BO_ 57 SRS_39: 3 SRS
 SG_ NEW_SIGNAL_2 : 7|8@0+ (1,0) [0|0] "" XXX
 SG_ NEW_SIGNAL_3 : 14|9@0+ (1,0) [0|0] "" XXX
 SG_ NEW_SIGNAL_1 : 15|1@0+ (1,0) [0|0] "" XXX
 SG_ CHECKSUM : 19|4@0+ (1,0) [0|0] "" XXX
 SG_ COUNTER : 21|2@0+ (1,0) [0|0] "" XXX

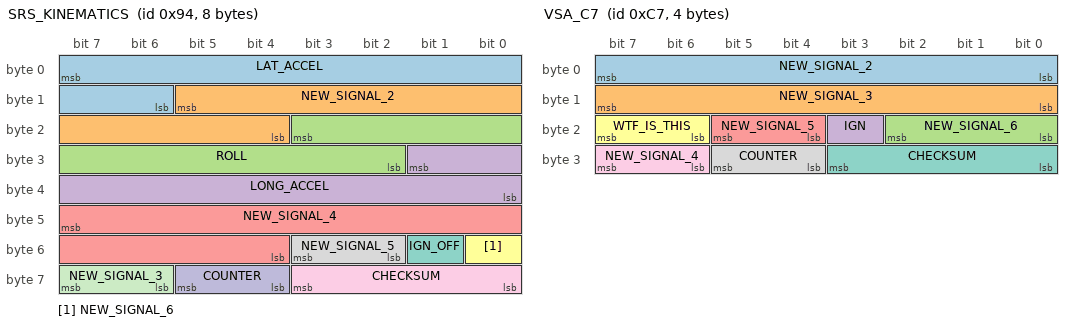
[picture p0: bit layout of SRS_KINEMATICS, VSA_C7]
BO_ 148 SRS_KINEMATICS: 8 SRS
 SG_ LAT_ACCEL : 7|10@0+ (-0.035,17.92) [0|0] "" XXX
 SG_ NEW_SIGNAL_2 : 13|10@0+ (1,0) [0|0] "" XXX
 SG_ ROLL : 19|10@0+ (1,-507) [0|0] "" XXX
 SG_ LONG_ACCEL : 25|10@0+ (-0.035,17.92) [0|0] "" XXX
 SG_ NEW_SIGNAL_4 : 47|12@0+ (1,0) [0|0] "" XXX
 SG_ NEW_SIGNAL_6 : 48|1@0+ (1,0) [0|0] "" XXX
 SG_ IGN_OFF : 49|1@0+ (1,0) [0|0] "" XXX
 SG_ NEW_SIGNAL_5 : 51|2@0+ (1,0) [0|0] "" XXX
 SG_ CHECKSUM : 59|4@0+ (1,0) [0|0] "" XXX
 SG_ COUNTER : 61|2@0+ (1,0) [0|0] "" XXX
 SG_ NEW_SIGNAL_3 : 63|2@0+ (1,0) [0|0] "" XXX

BO_ 199 VSA_C7: 4 VSA
 SG_ NEW_SIGNAL_2 : 7|8@0+ (1,0) [0|0] "" XXX
 SG_ NEW_SIGNAL_3 : 15|8@0+ (1,0) [0|0] "" XXX
 SG_ NEW_SIGNAL_6 : 18|3@0+ (1,0) [0|0] "" XXX
 SG_ IGN : 19|1@0+ (1,0) [0|0] "" XXX
 SG_ NEW_SIGNAL_5 : 21|2@0+ (1,0) [0|0] "" XXX
 SG_ WTF_IS_THIS : 23|2@0+ (1,0) [0|0] "" XXX
 SG_ CHECKSUM : 27|4@0+ (1,0) [0|0] "" XXX
 SG_ COUNTER : 29|2@0+ (1,0) [0|0] "" XXX
 SG_ NEW_SIGNAL_4 : 31|2@0+ (1,0) [0|0] "" XXX

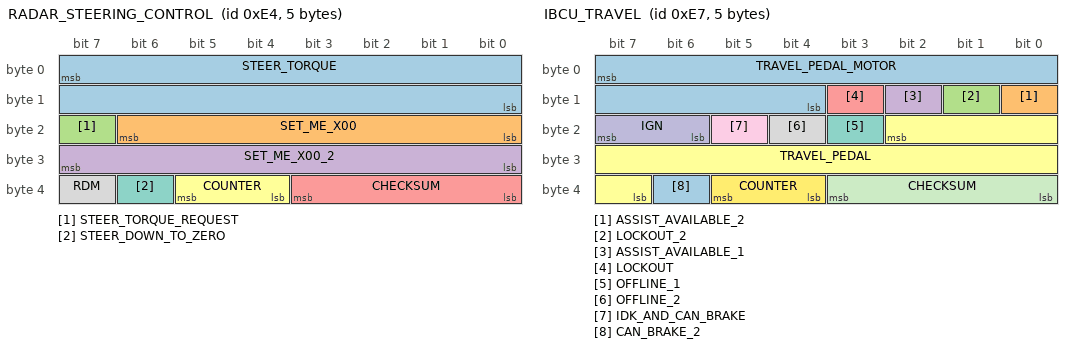
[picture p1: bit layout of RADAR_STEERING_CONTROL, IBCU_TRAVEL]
BO_ 228 RADAR_STEERING_CONTROL: 5 RADAR
 SG_ STEER_TORQUE : 7|16@0- (1,0) [0|0] "" XXX
 SG_ SET_ME_X00 : 22|7@0+ (1,0) [0|0] "" XXX
 SG_ STEER_TORQUE_REQUEST : 23|1@0+ (1,0) [0|0] "" XXX
 SG_ SET_ME_X00_2 : 31|8@0+ (1,0) [0|0] "" XXX
 SG_ CHECKSUM : 35|4@0+ (1,0) [0|0] "" XXX
 SG_ COUNTER : 37|2@0+ (1,0) [0|0] "" XXX
 SG_ STEER_DOWN_TO_ZERO : 38|1@0+ (1,0) [0|0] "" XXX
 SG_ RDM : 39|1@0+ (1,0) [0|0] "" XXX

BO_ 229 BOSCH_SUPPLEMENTAL_1: 8 CAM
 SG_ SET_ME_X04 : 0|8@1+ (1,0) [0|0] "" XXX
 SG_ SET_ME_X00 : 8|8@1+ (1,0) [0|0] "" XXX
 SG_ SET_ME_X80 : 16|8@1+ (1,0) [0|0] "" XXX
 SG_ SET_ME_X10 : 24|8@1+ (1,0) [0|0] "" XXX
 SG_ CHECKSUM : 59|4@0+ (1,0) [0|0] "" XXX
 SG_ COUNTER : 61|2@0+ (1,0) [0|0] "" XXX

BO_ 231 IBCU_TRAVEL: 5 IBCU
 SG_ TRAVEL_PEDAL_MOTOR : 7|12@0+ (1,0) [0|0] "" XXX
 SG_ ASSIST_AVAILABLE_2 : 8|1@0+ (1,0) [0|0] "" XXX
 SG_ LOCKOUT_2 : 9|1@0+ (1,0) [0|0] "" XXX
 SG_ ASSIST_AVAILABLE_1 : 10|1@0+ (1,0) [0|0] "" XXX
 SG_ LOCKOUT : 11|1@0+ (1,0) [0|0] "" XXX
 SG_ TRAVEL_PEDAL : 18|12@0+ (1,0) [0|0] "" XXX
 SG_ OFFLINE_1 : 19|1@0+ (1,0) [0|0] "" XXX
 SG_ OFFLINE_2 : 20|1@0+ (1,0) [0|0] "" XXX
 SG_ IDK_AND_CAN_BRAKE : 21|1@0+ (1,0) [0|0] "" XXX
 SG_ IGN : 23|2@0+ (1,0) [0|0] "" XXX
 SG_ CHECKSUM : 35|4@0+ (1,0) [0|0] "" XXX
 SG_ COUNTER : 37|2@0+ (1,0) [0|0] "" XXX
 SG_ CAN_BRAKE_2 : 38|1@0+ (1,0) [0|0] "" XXX

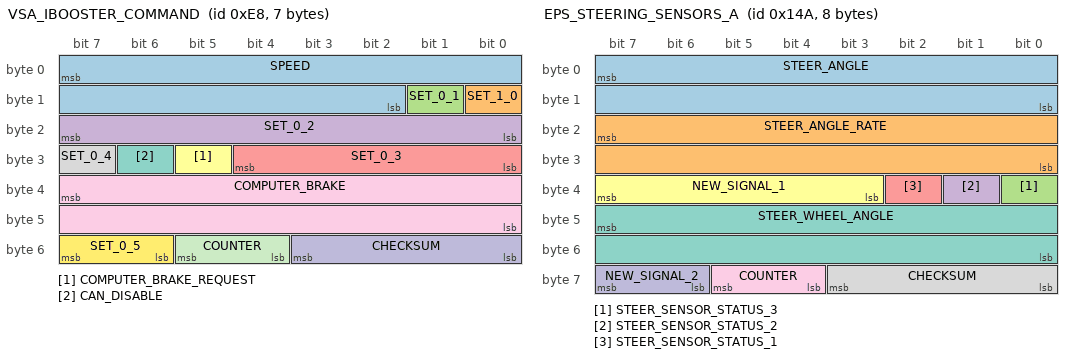
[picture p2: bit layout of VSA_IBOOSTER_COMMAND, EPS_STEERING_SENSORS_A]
BO_ 232 VSA_IBOOSTER_COMMAND: 7 VSA
 SG_ SPEED : 7|14@0+ (0.06,0) [0|0] "" XXX
 SG_ SET_1_0 : 8|1@0+ (1,0) [0|0] "" XXX
 SG_ SET_0_1 : 9|1@0+ (1,0) [0|0] "" XXX
 SG_ SET_0_2 : 23|8@0+ (1,0) [0|0] "" XXX
 SG_ SET_0_3 : 28|5@0+ (1,0) [0|0] "" XXX
 SG_ COMPUTER_BRAKE_REQUEST : 29|1@0+ (1,0) [0|0] "" XXX
 SG_ CAN_DISABLE : 30|1@0+ (1,0) [0|0] "" XXX
 SG_ SET_0_4 : 31|1@0+ (1,0) [0|0] "" XXX
 SG_ COMPUTER_BRAKE : 39|16@0+ (1,-32256) [0|0] "" XXX
 SG_ CHECKSUM : 51|4@0+ (1,0) [0|0] "" XXX
 SG_ COUNTER : 53|2@0+ (1,0) [0|0] "" XXX
 SG_ SET_0_5 : 55|2@0+ (1,0) [0|0] "" XXX

BO_ 304 PCM_GATEWAYFORWARD_GAS_PEDAL_2: 8 PCM
 SG_ ENGINE_TORQUE_ESTIMATE : 7|16@0- (0.1,0) [0|0] "" XXX
 SG_ ENGINE_TORQUE_REQUEST : 23|16@0- (0.1,0) [0|0] "" XXX
 SG_ CAR_GAS : 39|8@0+ (0.465116279,0) [0|0] "" XXX
 SG_ NEW_SIGNAL_8 : 40|1@0+ (1,0) [0|1] "" XXX
 SG_ RELATED_IDLE_STOP : 41|1@0+ (1,0) [0|0] "" XXX
 SG_ NEW_SIGNAL_6 : 43|2@0+ (1,0) [0|3] "" XXX
 SG_ GAS_PRESSED : 44|1@0+ (1,0) [0|0] "" XXX
 SG_ NEW_SIGNAL_3 : 45|1@0+ (1,0) [0|1] "" XXX
 SG_ RELATED_IDLE_STOP2 : 46|1@0+ (1,0) [0|0] "" XXX
 SG_ NEW_SIGNAL_2 : 47|1@0+ (1,0) [0|1] "" XXX
 SG_ NEUTRAL : 48|1@0+ (1,0) [0|1] "" XXX
 SG_ REVERSE : 49|1@0+ (1,0) [0|1] "" XXX
 SG_ CLUTCH : 50|1@0+ (1,0) [0|0] "" XXX
 SG_ NEW_SIGNAL_7 : 51|1@0+ (1,0) [0|1] "" XXX
 SG_ NEW_SIGNAL_1 : 52|1@0+ (1,0) [0|1] "" XXX
 SG_ NEW_SIGNAL_5 : 55|3@0+ (1,0) [0|7] "" XXX
 SG_ CHECKSUM : 59|4@0+ (1,0) [0|0] "" XXX
 SG_ COUNTER : 61|2@0+ (1,0) [0|0] "" XXX

BO_ 330 EPS_STEERING_SENSORS_A: 8 EPS
 SG_ STEER_ANGLE : 7|16@0- (-0.1,0) [0|0] "" XXX
 SG_ STEER_ANGLE_RATE : 23|16@0- (-1,0) [0|0] "" XXX
 SG_ STEER_SENSOR_STATUS_3 : 32|1@0+ (1,0) [0|0] "" XXX
 SG_ STEER_SENSOR_STATUS_2 : 33|1@0+ (1,0) [0|0] "" XXX
 SG_ STEER_SENSOR_STATUS_1 : 34|1@0+ (1,0) [0|0] "" XXX
 SG_ NEW_SIGNAL_1 : 39|5@0+ (1,0) [0|0] "" XXX
 SG_ STEER_WHEEL_ANGLE : 47|16@0- (-0.1,0) [0|0] "" XXX
 SG_ CHECKSUM : 59|4@0+ (1,0) [0|0] "" XXX
 SG_ COUNTER : 61|2@0+ (1,0) [0|0] "" XXX
 SG_ NEW_SIGNAL_2 : 63|2@0+ (1,0) [0|0] "" XXX

BO_ 340 CRV_IDK_154: 8 XXX
 SG_ NEW_SIGNAL_1 : 7|8@0+ (1,0) [0|0] "" XXX
 SG_ NEW_SIGNAL_2 : 15|8@0+ (1,0) [0|0] "" XXX
 SG_ NEW_SIGNAL_3 : 23|8@0+ (1,0) [0|0] "" XXX
 SG_ NEW_SIGNAL_4 : 31|32@0+ (1,0) [0|0] "" XXX
 SG_ CHECKSUM : 59|4@0+ (1,0) [0|0] "" XXX
 SG_ COUNTER : 61|2@0+ (1,0) [0|0] "" XXX
 SG_ NEW_SIGNAL_5 : 63|2@0+ (1,0) [0|0] "" XXX

BO_ 342 STEERING_SENSORS_B: 6 EPS
 SG_ STEER_ANGLE : 7|16@0- (-0.1,0) [0|0] "" XXX
 SG_ STEER_ANGLE_RATE : 23|16@0- (-1,0) [0|0] "" XXX
 SG_ CHECKSUM : 43|4@0+ (1,0) [0|0] "" XXX
 SG_ COUNTER : 45|2@0+ (1,0) [0|0] "" XXX

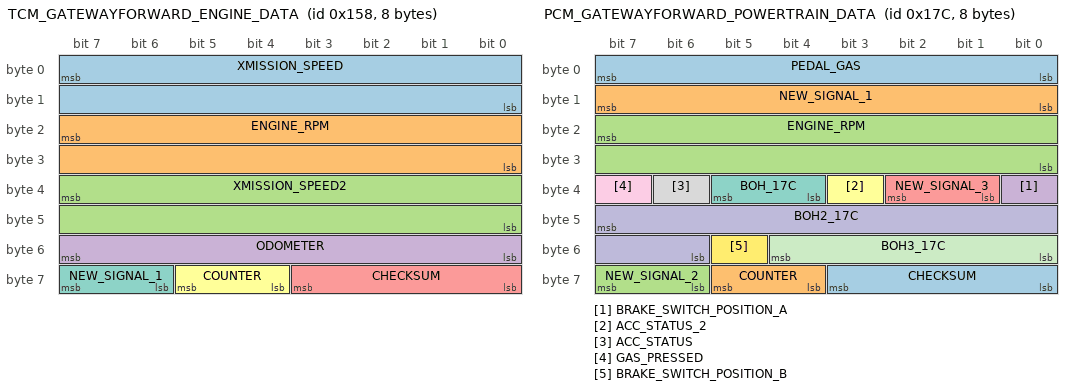
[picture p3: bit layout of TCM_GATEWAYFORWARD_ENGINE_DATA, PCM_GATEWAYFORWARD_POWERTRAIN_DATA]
BO_ 344 TCM_GATEWAYFORWARD_ENGINE_DATA: 8 TCM
 SG_ XMISSION_SPEED : 7|16@0+ (0.01,0) [0|0] "" XXX
 SG_ ENGINE_RPM : 23|16@0+ (1,0) [0|0] "" XXX
 SG_ XMISSION_SPEED2 : 39|16@0+ (0.01,0) [0|0] "" XXX
 SG_ ODOMETER : 55|8@0+ (10,0) [0|0] "" XXX
 SG_ CHECKSUM : 59|4@0+ (1,0) [0|0] "" XXX
 SG_ COUNTER : 61|2@0+ (1,0) [0|0] "" XXX
 SG_ NEW_SIGNAL_1 : 63|2@0+ (1,0) [0|0] "" XXX

BO_ 380 PCM_GATEWAYFORWARD_POWERTRAIN_DATA: 8 PCM
 SG_ PEDAL_GAS : 7|8@0+ (0.465116279,0) [0|0] "" XXX
 SG_ NEW_SIGNAL_1 : 15|8@0+ (1,0) [0|255] "" XXX
 SG_ ENGINE_RPM : 23|16@0+ (1,0) [0|0] "" XXX
 SG_ BRAKE_SWITCH_POSITION_A : 32|1@0+ (1,0) [0|0] "" XXX
 SG_ NEW_SIGNAL_3 : 34|2@0+ (1,0) [0|0] "" XXX
 SG_ ACC_STATUS_2 : 35|1@0+ (1,0) [0|0] "" XXX
 SG_ BOH_17C : 37|2@0+ (1,0) [0|0] "" XXX
 SG_ ACC_STATUS : 38|1@0+ (1,0) [0|0] "" XXX
 SG_ GAS_PRESSED : 39|1@0+ (1,0) [0|0] "" XXX
 SG_ BOH2_17C : 47|10@0+ (1,0) [0|0] "" XXX
 SG_ BOH3_17C : 52|5@0+ (1,0) [0|0] "" XXX
 SG_ BRAKE_SWITCH_POSITION_B : 53|1@0+ (1,0) [0|0] "" XXX
 SG_ CHECKSUM : 59|4@0+ (1,0) [0|0] "" XXX
 SG_ COUNTER : 61|2@0+ (1,0) [0|0] "" XXX
 SG_ NEW_SIGNAL_2 : 63|2@0+ (1,0) [0|0] "" XXX

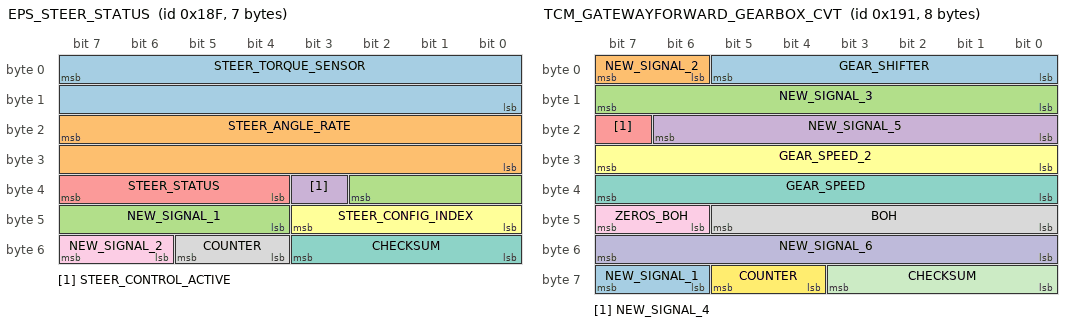
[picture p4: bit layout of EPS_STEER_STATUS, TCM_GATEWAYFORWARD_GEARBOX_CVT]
BO_ 399 EPS_STEER_STATUS: 7 EPS
 SG_ STEER_TORQUE_SENSOR : 7|16@0- (-0.001,0) [0|0] "" XXX
 SG_ STEER_ANGLE_RATE : 23|16@0- (-0.1,0) [0|0] "" XXX
 SG_ NEW_SIGNAL_1 : 34|7@0+ (1,0) [0|0] "" XXX
 SG_ STEER_CONTROL_ACTIVE : 35|1@0+ (1,0) [0|0] "" XXX
 SG_ STEER_STATUS : 39|4@0+ (1,0) [0|0] "" XXX
 SG_ STEER_CONFIG_INDEX : 43|4@0+ (1,0) [0|0] "" XXX
 SG_ CHECKSUM : 51|4@0+ (1,0) [0|0] "" XXX
 SG_ COUNTER : 53|2@0+ (1,0) [0|0] "" XXX
 SG_ NEW_SIGNAL_2 : 55|2@0+ (1,0) [0|0] "" XXX

BO_ 401 TCM_GATEWAYFORWARD_GEARBOX_CVT: 8 TCM
 SG_ GEAR_SHIFTER : 5|6@0+ (1,0) [0|0] "" XXX
 SG_ NEW_SIGNAL_2 : 7|2@0+ (1,0) [0|0] "" XXX
 SG_ NEW_SIGNAL_3 : 15|8@0+ (1,0) [0|0] "" XXX
 SG_ NEW_SIGNAL_5 : 22|7@0+ (1,0) [0|0] "" XXX
 SG_ NEW_SIGNAL_4 : 23|1@0+ (1,0) [0|0] "" XXX
 SG_ GEAR_SPEED_2 : 31|8@0+ (-0.243,41.067) [0|0] "" XXX
 SG_ GEAR_SPEED : 39|8@0+ (-0.243,41.067) [0|0] "" XXX
 SG_ BOH : 45|6@0+ (1,0) [0|0] "" XXX
 SG_ ZEROS_BOH : 47|2@0+ (1,0) [0|0] "" XXX
 SG_ NEW_SIGNAL_6 : 55|8@0+ (1,0) [0|0] "" XXX
 SG_ CHECKSUM : 59|4@0+ (1,0) [0|0] "" XXX
 SG_ COUNTER : 61|2@0+ (1,0) [0|0] "" XXX
 SG_ NEW_SIGNAL_1 : 63|2@0+ (1,0) [0|0] "" XXX

BO_ 411 WHEEL_TICKS_2: 5 VSA
 SG_ NEW_SIGNAL_1 : 7|8@0+ (1,0) [0|0] "" XXX
 SG_ NEW_SIGNAL_2 : 15|8@0+ (1,0) [0|0] "" XXX
 SG_ NEW_SIGNAL_3 : 23|8@0+ (1,0) [0|0] "" XXX
 SG_ NEW_SIGNAL_4 : 31|8@0+ (1,0) [0|0] "" XXX
 SG_ CHECKSUM : 35|4@0+ (1,0) [0|0] "" XXX
 SG_ COUNTER : 37|2@0+ (1,0) [0|0] "" XXX

BO_ 419 GEARBOX_10SPEED: 8 TCM
 SG_ GEAR_SHIFTER : 24|8@1+ (1,0) [0|0] "" XXX
 SG_ GEAR : 32|8@1+ (1,0) [0|0] "" XXX
 SG_ CHECKSUM : 59|4@0+ (1,0) [0|0] "" XXX
 SG_ COUNTER : 61|2@0+ (1,0) [0|0] "" XXX

BO_ 420 VSA_STATUS: 8 VSA
 SG_ BRAKE_PEDAL_TRAVEL : 0|9@0+ (0.182819,0) [0|0] "" XXX
 SG_ NEW_SIGNAL_1 : 7|7@0+ (1,0) [0|0] "" XXX
 SG_ TCS_ACTIVE_1 : 16|1@0+ (1,0) [0|0] "" XXX
 SG_ ABS_ACTIVE_1 : 17|1@0+ (1,0) [0|0] "" XXX
 SG_ NEW_SIGNAL_2 : 22|5@0+ (1,0) [0|0] "" XXX
 SG_ ACC_FRICTION_BRAKE : 23|1@0+ (1,0) [0|0] "" XXX
 SG_ NEW_SIGNAL_4 : 24|10@0+ (1,0) [0|0] "" XXX
 SG_ NEW_SIGNAL_8 : 25|1@0+ (1,0) [0|0] "" XXX
 SG_ NEW_SIGNAL_7 : 26|1@0+ (1,0) [0|0] "" XXX
 SG_ TCS_LIGHT_2_IDK : 27|1@0+ (1,0) [0|0] "" XXX
 SG_ TCS_DISABLED : 28|1@0+ (1,0) [0|0] "" XXX
 SG_ TCS_LIGHT : 29|1@0+ (1,0) [0|0] "" XXX
 SG_ NEW_SIGNAL_3 : 31|2@0+ (1,0) [0|0] "" XXX
 SG_ NEW_SIGNAL_5 : 44|8@0+ (1,0) [0|0] "" XXX
 SG_ BRAKE_HOLD_ENABLED : 45|1@0+ (1,0) [0|0] "" XXX
 SG_ BRAKE_HOLD_ACTIVE_1 : 46|1@0+ (1,0) [0|0] "" XXX
 SG_ NEW_SIGNAL_6 : 51|4@0+ (1,0) [0|0] "" XXX
 SG_ VSA_STANDSTILL : 52|1@0+ (1,0) [0|0] "" XXX
 SG_ CHECKSUM : 59|4@0+ (1,0) [0|0] "" XXX
 SG_ COUNTER : 61|2@0+ (1,0) [0|0] "" XXX
 SG_ ABS_ACTIVE_2 : 62|1@0+ (1,0) [0|0] "" XXX
 SG_ STABILITY_BRAKE_ACTIVE : 63|1@0+ (1,0) [0|0] "" XXX

BO_ 423 OBD2_TCM_1A7: 2 TCM
 SG_ NEW_SIGNAL_3 : 7|8@0+ (1,0) [0|0] "" XXX
 SG_ CHECKSUM : 11|4@0+ (1,0) [0|0] "" XXX
 SG_ COUNTER : 13|2@0+ (1,0) [0|0] "" XXX
 SG_ NEW_SIGNAL_4 : 15|2@0+ (1,0) [0|0] "" XXX

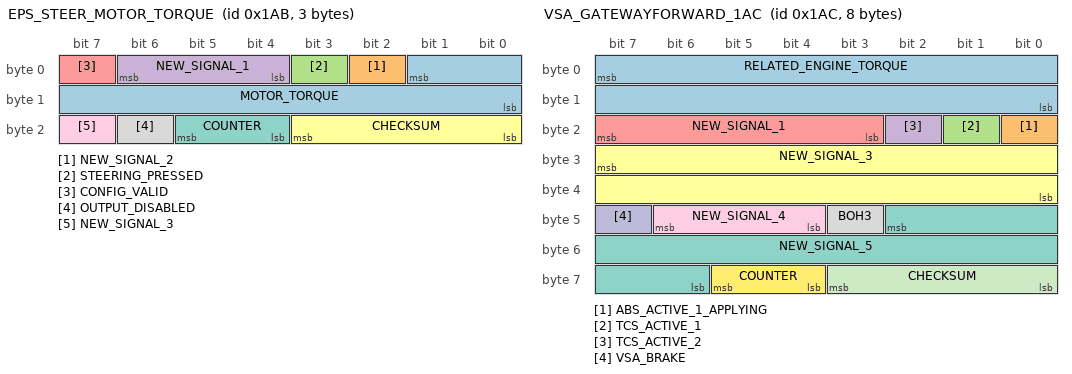
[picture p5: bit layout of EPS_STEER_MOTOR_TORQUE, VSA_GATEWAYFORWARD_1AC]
BO_ 427 EPS_STEER_MOTOR_TORQUE: 3 EPS
 SG_ MOTOR_TORQUE : 1|10@0+ (1,0) [0|0] "" XXX
 SG_ NEW_SIGNAL_2 : 2|1@0+ (1,0) [0|0] "" XXX
 SG_ STEERING_PRESSED : 3|1@0+ (1,0) [0|0] "" XXX
 SG_ NEW_SIGNAL_1 : 6|3@0+ (1,0) [0|0] "" XXX
 SG_ CONFIG_VALID : 7|1@0+ (1,0) [0|0] "" XXX
 SG_ CHECKSUM : 19|4@0+ (1,0) [0|0] "" XXX
 SG_ COUNTER : 21|2@0+ (1,0) [0|0] "" XXX
 SG_ OUTPUT_DISABLED : 22|1@0+ (1,0) [0|0] "" XXX
 SG_ NEW_SIGNAL_3 : 23|1@0+ (1,0) [0|0] "" XXX

BO_ 428 VSA_GATEWAYFORWARD_1AC: 8 VSA
 SG_ RELATED_ENGINE_TORQUE : 7|16@0- (0.1,0) [0|0] "" XXX
 SG_ ABS_ACTIVE_1_APPLYING : 16|1@0+ (1,0) [0|1] "" XXX
 SG_ TCS_ACTIVE_1 : 17|1@0+ (1,0) [0|0] "" XXX
 SG_ TCS_ACTIVE_2 : 18|1@0+ (1,0) [0|0] "" XXX
 SG_ NEW_SIGNAL_1 : 23|5@0+ (1,0) [0|0] "" XXX
 SG_ NEW_SIGNAL_3 : 31|16@0+ (1,0) [0|0] "" XXX
 SG_ NEW_SIGNAL_5 : 42|13@0+ (1,0) [0|0] "" XXX
 SG_ BOH3 : 43|1@0+ (1,0) [0|0] "" XXX
 SG_ NEW_SIGNAL_4 : 46|3@0+ (1,0) [0|0] "" XXX
 SG_ VSA_BRAKE : 47|1@0+ (1,0) [0|0] "" XXX
 SG_ CHECKSUM : 59|4@0+ (1,0) [0|0] "" XXX
 SG_ COUNTER : 61|2@0+ (1,0) [0|0] "" XXX

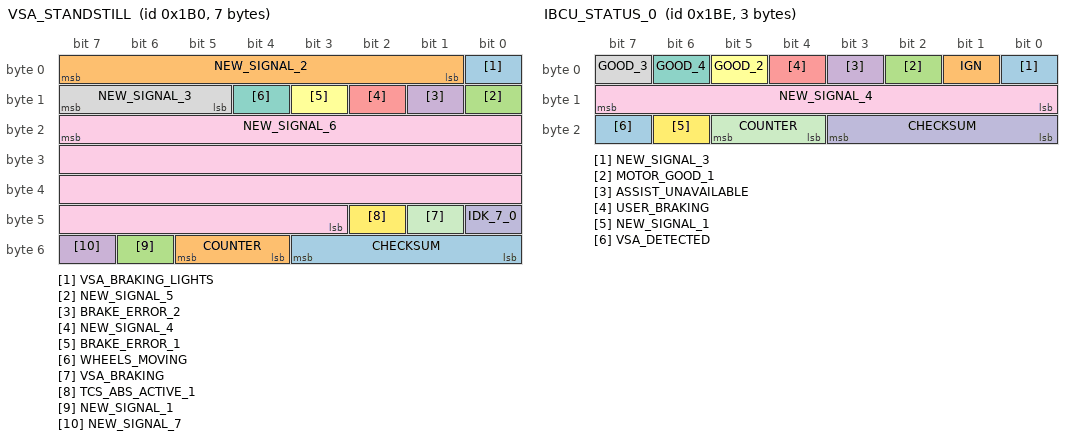
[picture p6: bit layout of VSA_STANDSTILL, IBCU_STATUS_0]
BO_ 432 VSA_STANDSTILL: 7 VSA
 SG_ VSA_BRAKING_LIGHTS : 0|1@0+ (1,0) [0|0] "" XXX
 SG_ NEW_SIGNAL_2 : 7|7@0+ (1,0) [0|0] "" XXX
 SG_ NEW_SIGNAL_5 : 8|1@0+ (1,0) [0|0] "" XXX
 SG_ BRAKE_ERROR_2 : 9|1@0+ (1,0) [0|0] "" XXX
 SG_ NEW_SIGNAL_4 : 10|1@0+ (1,0) [0|0] "" XXX
 SG_ BRAKE_ERROR_1 : 11|1@0+ (1,0) [0|0] "" XXX
 SG_ WHEELS_MOVING : 12|1@0+ (1,0) [0|0] "" XXX
 SG_ NEW_SIGNAL_3 : 15|3@0+ (1,0) [0|0] "" XXX
 SG_ NEW_SIGNAL_6 : 23|29@0+ (1,0) [0|0] "" XXX
 SG_ IDK_7_0 : 40|1@0+ (1,0) [0|0] "" XXX
 SG_ VSA_BRAKING : 41|1@0+ (1,0) [0|0] "" XXX
 SG_ TCS_ABS_ACTIVE_1 : 42|1@0+ (1,0) [0|0] "" XXX
 SG_ CHECKSUM : 51|4@0+ (1,0) [0|0] "" XXX
 SG_ COUNTER : 53|2@0+ (1,0) [0|0] "" XXX
 SG_ NEW_SIGNAL_1 : 54|1@0+ (1,0) [0|0] "" XXX
 SG_ NEW_SIGNAL_7 : 55|1@0+ (1,0) [0|0] "" XXX

BO_ 441 VSA_WHEEL_TICKS: 5 VSA
 SG_ ENCODER_FL : 7|8@0+ (1,0) [0|0] "" XXX
 SG_ ENCODER_FR : 15|8@0+ (1,0) [0|0] "" XXX
 SG_ ENCODER_RL : 23|8@0+ (1,0) [0|0] "" XXX
 SG_ ENCODER_RR : 31|8@0+ (1,0) [0|0] "" XXX
 SG_ CHECKSUM : 35|4@0+ (1,0) [0|0] "" XXX
 SG_ COUNTER : 37|2@0+ (1,0) [0|0] "" XXX
 SG_ NEW_SIGNAL_1 : 39|2@0+ (1,0) [0|0] "" XXX

BO_ 446 IBCU_STATUS_0: 3 IBCU
 SG_ NEW_SIGNAL_3 : 0|1@0+ (1,0) [0|0] "" XXX
 SG_ IGN : 1|1@0+ (1,0) [0|0] "" XXX
 SG_ MOTOR_GOOD_1 : 2|1@0+ (1,0) [0|0] "" XXX
 SG_ ASSIST_UNAVAILABLE : 3|1@0+ (1,0) [0|0] "" XXX
 SG_ USER_BRAKING : 4|1@0+ (1,0) [0|0] "" XXX
 SG_ GOOD_2 : 5|1@0+ (1,0) [0|0] "" XXX
 SG_ GOOD_4 : 6|1@0+ (1,0) [0|0] "" XXX
 SG_ GOOD_3 : 7|1@0+ (1,0) [0|0] "" XXX
 SG_ NEW_SIGNAL_4 : 15|8@0+ (1,0) [0|0] "" XXX
 SG_ CHECKSUM : 19|4@0+ (1,0) [0|0] "" XXX
 SG_ COUNTER : 21|2@0+ (1,0) [0|0] "" XXX
 SG_ NEW_SIGNAL_1 : 22|1@0+ (1,0) [0|0] "" XXX
 SG_ VSA_DETECTED : 23|1@0+ (1,0) [0|0] "" XXX

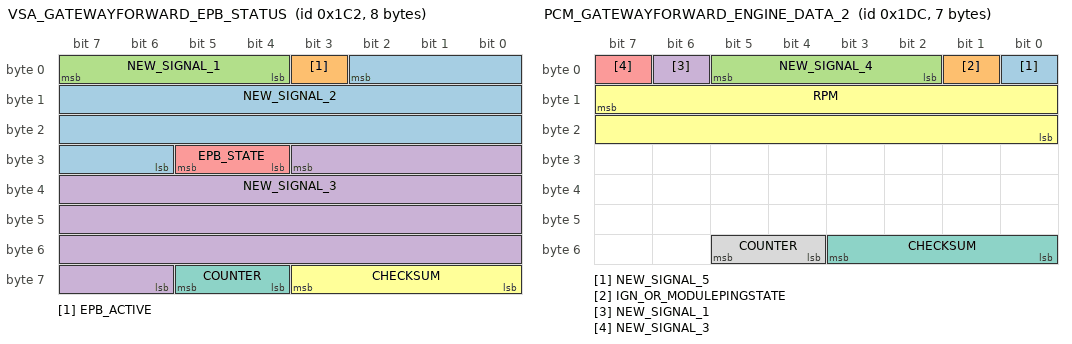
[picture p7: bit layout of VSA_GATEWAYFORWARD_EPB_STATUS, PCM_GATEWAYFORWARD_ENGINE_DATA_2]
BO_ 450 VSA_GATEWAYFORWARD_EPB_STATUS: 8 VSA
 SG_ NEW_SIGNAL_2 : 2|21@0+ (1,0) [0|0] "" XXX
 SG_ EPB_ACTIVE : 3|1@0+ (1,0) [0|0] "" XXX
 SG_ NEW_SIGNAL_1 : 7|4@0+ (1,0) [0|0] "" XXX
 SG_ NEW_SIGNAL_3 : 27|30@0+ (1,0) [0|0] "" XXX
 SG_ EPB_STATE : 29|2@0+ (1,0) [0|0] "" XXX
 SG_ CHECKSUM : 59|4@0+ (1,0) [0|0] "" XXX
 SG_ COUNTER : 61|2@0+ (1,0) [0|0] "" XXX

BO_ 464 VSA_WHEEL_SPEEDS: 8 VSA
 SG_ WHEEL_SPEED_FL : 7|15@0+ (0.01,0) [0|0] "" XXX
 SG_ WHEEL_SPEED_FR : 8|15@0+ (0.01,0) [0|0] "" XXX
 SG_ WHEEL_SPEED_RL : 25|15@0+ (0.01,0) [0|0] "" XXX
 SG_ WHEEL_SPEED_RR : 42|15@0+ (0.01,0) [0|0] "" XXX
 SG_ CHECKSUM : 59|4@0+ (1,0) [0|0] "" XXX

BO_ 469 IBCU_STATUS_1: 3 IBCU
 SG_ MAX_CAN_TRAVEL : 0|1@0+ (1,0) [0|0] "" XXX
 SG_ GOOD_2 : 1|1@0+ (1,0) [0|0] "" XXX
 SG_ GOOD : 2|1@0+ (1,0) [0|0] "" XXX
 SG_ SET_0_2 : 5|3@0+ (1,0) [0|0] "" XXX
 SG_ GOOD_5 : 6|1@0+ (1,0) [0|0] "" XXX
 SG_ SET_0_3 : 7|1@0+ (1,0) [0|0] "" XXX
 SG_ GOOD_3 : 8|1@0+ (1,0) [0|0] "" XXX
 SG_ SET_0_4 : 9|1@0+ (1,0) [0|0] "" XXX
 SG_ ASSIST_AVAILABLE : 10|1@0+ (1,0) [0|0] "" XXX
 SG_ LOCKOUT : 11|1@0+ (1,0) [0|0] "" XXX
 SG_ USER_BRAKING : 12|1@0+ (1,0) [0|0] "" XXX
 SG_ LOCKOUT_2 : 13|1@0+ (1,0) [0|0] "" XXX
 SG_ SET_1_1 : 14|1@0+ (1,0) [0|0] "" XXX
 SG_ GOOD_4 : 15|1@0+ (1,0) [0|0] "" XXX
 SG_ CHECKSUM : 19|4@0+ (1,0) [0|0] "" XXX
 SG_ COUNTER : 21|2@0+ (1,0) [0|0] "" XXX
 SG_ OFFLINE_BOH_ASSIST_AVAILABLE_OR_IGN_MAYBE : 22|1@0+ (1,0) [0|0] "" XXX
 SG_ OFFLINE_LOCKOUT_3 : 23|1@0+ (1,0) [0|0] "" XXX

BO_ 470 PCM_GATEWAYFORWARD_1D6: 2 PCM
 SG_ NEW_SIGNAL_1 : 7|10@0+ (1,0) [0|0] "" XXX
 SG_ CHECKSUM : 11|4@0+ (1,0) [0|0] "" XXX
 SG_ COUNTER : 13|2@0+ (1,0) [0|0] "" XXX

BO_ 474 CRV_IDK_1DA: 8 XXX
 SG_ NEW_SIGNAL_1 : 7|8@0+ (1,0) [0|0] "" XXX
 SG_ NEW_SIGNAL_2 : 15|8@0+ (1,0) [0|0] "" XXX
 SG_ NEW_SIGNAL_3 : 23|8@0+ (1,0) [0|0] "" XXX
 SG_ NEW_SIGNAL_4 : 31|32@0+ (1,0) [0|0] "" XXX
 SG_ CHECKSUM : 59|4@0+ (1,0) [0|0] "" XXX
 SG_ COUNTER : 61|2@0+ (1,0) [0|0] "" XXX
 SG_ NEW_SIGNAL_5 : 63|2@0+ (1,0) [0|0] "" XXX

BO_ 476 PCM_GATEWAYFORWARD_ENGINE_DATA_2: 7 PCM
 SG_ NEW_SIGNAL_5 : 0|1@0+ (1,0) [0|0] "" XXX
 SG_ IGN_OR_MODULEPINGSTATE : 1|1@0+ (1,0) [0|0] "" XXX
 SG_ NEW_SIGNAL_4 : 5|4@0+ (1,0) [0|0] "" XXX
 SG_ NEW_SIGNAL_1 : 6|1@0+ (1,0) [0|0] "" XXX
 SG_ NEW_SIGNAL_3 : 7|1@0+ (1,0) [0|0] "" XXX
 SG_ RPM : 15|16@0+ (1,0) [0|0] "" XXX
 SG_ CHECKSUM : 51|4@0+ (1,0) [0|0] "" XXX
 SG_ COUNTER : 53|2@0+ (1,0) [0|0] "" XXX

BO_ 477 PCM_GATEWAYFORWARD_1DD: 8 PCM
 SG_ NEW_SIGNAL_1 : 7|16@0- (1,0) [0|0] "" XXX
 SG_ NEW_SIGNAL_2 : 23|16@0- (1,0) [0|0] "" XXX
 SG_ NEW_SIGNAL_5 : 39|26@0+ (1,0) [0|0] "" XXX
 SG_ CHECKSUM : 59|4@0+ (1,0) [0|0] "" XXX
 SG_ COUNTER : 61|2@0+ (1,0) [0|0] "" XXX

BO_ 479 RADAR_ACC_CONTROL: 8 RADAR
 SG_ GAS_COMMAND : 7|16@0- (0.1,0) [0|0] "" XXX
 SG_ SET_TO_0 : 20|5@0+ (1,0) [0|0] "" XXX
 SG_ CONTROL_ON : 23|3@0+ (1,0) [0|0] "" XXX
 SG_ ACCEL_COMMAND : 31|11@0- (0.01,0) [0|0] "" XXX
 SG_ NEW_SIGNAL_3 : 32|1@0+ (1,0) [0|0] "" XXX
 SG_ AEB_STATUS : 33|1@0+ (1,0) [0|0] "" XXX
 SG_ BRAKE_REQUEST : 34|1@0+ (1,0) [0|0] "" XXX
 SG_ STANDSTILL_REQUEST : 35|1@0+ (1,0) [0|0] "" XXX
 SG_ STANDSTILL_RELEASE : 36|1@0+ (1,0) [0|0] "" XXX
 SG_ NEW_SIGNAL_2 : 42|3@0+ (1,0) [0|0] "" XXX
 SG_ AEB_PREPARE : 43|1@0+ (1,0) [0|0] "" XXX
 SG_ NEW_SIGNAL_1 : 46|3@0+ (1,0) [0|0] "" XXX
 SG_ AEB_BRAKING : 47|1@0+ (1,0) [0|0] "" XXX
 SG_ NEW_SIGNAL_4 : 55|8@0+ (1,0) [0|0] "" XXX
 SG_ CHECKSUM : 59|4@0+ (1,0) [0|0] "" XXX
 SG_ COUNTER : 61|2@0+ (1,0) [0|0] "" XXX
 SG_ BRAKE_LIGHTS : 62|1@0+ (1,0) [0|0] "" XXX
 SG_ NEW_SIGNAL_5 : 63|1@0+ (1,0) [0|0] "" XXX

BO_ 490 VSA_KINEMATICS: 8 VSA
 SG_ LAT_ACCEL : 7|16@0- (0.0015,0) [0|0] "" XXX
 SG_ LONG_ACCEL : 23|16@0- (0.0015,0) [0|0] "" XXX
 SG_ NEW_SIGNAL_1 : 39|26@0+ (1,0) [0|0] "" XXX
 SG_ CHECKSUM : 59|4@0+ (1,0) [0|0] "" XXX
 SG_ COUNTER : 61|2@0+ (1,0) [0|0] "" XXX

BO_ 493 PCM_GATEWAYFORWARD_ACC_STATE: 5 PCM
 SG_ NEW_SIGNAL_3 : 4|31@0+ (1,0) [0|0] "" XXX
 SG_ NEW_SIGNAL_1 : 5|1@0+ (1,0) [0|0] "" XXX
 SG_ NEW_SIGNAL_2 : 6|1@0+ (1,0) [0|0] "" XXX
 SG_ CONTROL_ON : 7|1@0+ (1,0) [0|0] "" XXX
 SG_ CHECKSUM : 35|4@0+ (1,0) [0|0] "" XXX
 SG_ COUNTER : 37|2@0+ (1,0) [0|0] "" XXX

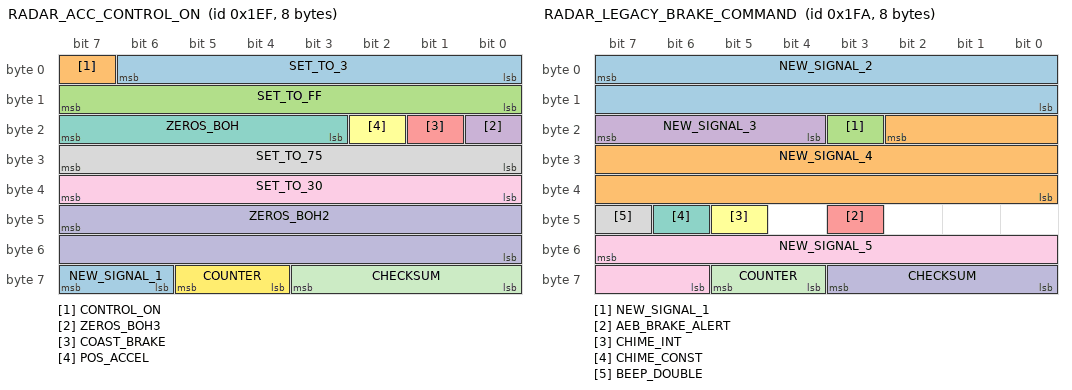
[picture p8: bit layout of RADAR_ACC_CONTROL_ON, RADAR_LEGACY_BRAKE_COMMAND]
BO_ 495 RADAR_ACC_CONTROL_ON: 8 RADAR
 SG_ SET_TO_3 : 6|7@0+ (1,0) [0|0] "" XXX
 SG_ CONTROL_ON : 7|1@0+ (1,0) [0|0] "" XXX
 SG_ SET_TO_FF : 15|8@0+ (1,0) [0|0] "" XXX
 SG_ ZEROS_BOH3 : 16|1@0+ (1,0) [0|0] "" XXX
 SG_ COAST_BRAKE : 17|1@0+ (1,0) [0|0] "" XXX
 SG_ POS_ACCEL : 18|1@0+ (1,0) [0|0] "" XXX
 SG_ ZEROS_BOH : 23|5@0+ (1,0) [0|0] "" XXX
 SG_ SET_TO_75 : 31|8@0+ (1,0) [0|0] "" XXX
 SG_ SET_TO_30 : 39|8@0+ (1,0) [0|0] "" XXX
 SG_ ZEROS_BOH2 : 47|16@0+ (1,0) [0|0] "" XXX
 SG_ CHECKSUM : 59|4@0+ (1,0) [0|0] "" XXX
 SG_ COUNTER : 61|2@0+ (1,0) [0|0] "" XXX
 SG_ NEW_SIGNAL_1 : 63|2@0+ (1,0) [0|0] "" XXX

BO_ 506 RADAR_LEGACY_BRAKE_COMMAND: 8 XXX
 SG_ NEW_SIGNAL_2 : 7|16@0+ (1,0) [0|0] "" XXX
 SG_ NEW_SIGNAL_4 : 18|19@0+ (1,0) [0|0] "" XXX
 SG_ NEW_SIGNAL_1 : 19|1@0+ (1,0) [0|0] "" XXX
 SG_ NEW_SIGNAL_3 : 23|4@0+ (1,0) [0|0] "" XXX
 SG_ AEB_BRAKE_ALERT : 43|1@1+ (1,0) [0|0] "" XXX
 SG_ CHIME_INT : 45|1@0+ (1,0) [0|1] "" XXX
 SG_ CHIME_CONST : 46|1@0+ (1,0) [0|1] "" XXX
 SG_ BEEP_DOUBLE : 47|1@0+ (1,0) [0|1] "" XXX
 SG_ NEW_SIGNAL_5 : 55|10@0+ (1,0) [0|0] "" XXX
 SG_ CHECKSUM : 59|4@0+ (1,0) [0|0] "" XXX
 SG_ COUNTER : 61|2@0+ (1,0) [0|0] "" XXX

BO_ 507 OBD2_IDK_1FB: 1 XXX
 SG_ CHECKSUM : 3|4@0+ (1,0) [0|0] "" XXX
 SG_ COUNTER : 5|2@0+ (1,0) [0|0] "" XXX
 SG_ NEW_SIGNAL_4 : 6|1@0+ (1,0) [0|0] "" XXX
 SG_ NEW_SIGNAL_1 : 7|1@0+ (1,0) [0|0] "" XXX

BO_ 513 NEW_MSG_6: 8 XXX
 SG_ NEW_SIGNAL_1 : 4|11@0+ (1,0) [0|0] "" XXX
 SG_ NEW_SIGNAL_4 : 29|4@0+ (1,0) [0|0] "" XXX
 SG_ NEW_SIGNAL_3 : 39|8@0+ (1,0) [0|0] "" XXX
 SG_ NEW_SIGNAL_6 : 59|4@0+ (1,0) [0|0] "" XXX
 SG_ NEW_SIGNAL_5 : 61|2@0+ (1,0) [0|0] "" XXX

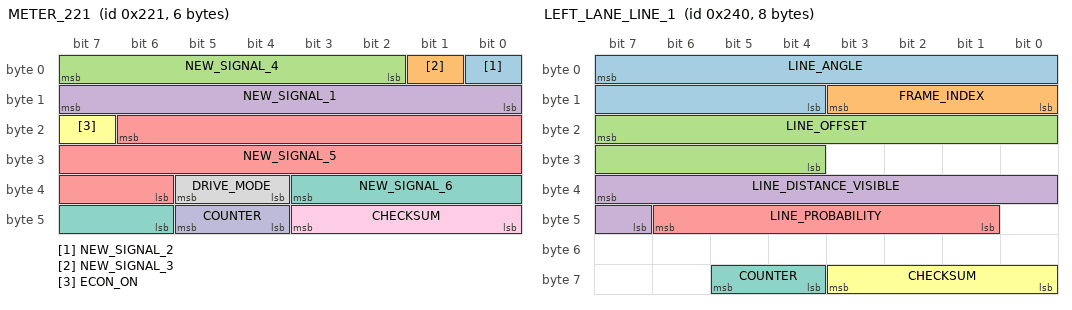
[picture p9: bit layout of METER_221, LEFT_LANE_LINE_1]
BO_ 545 METER_221: 6 METER
 SG_ NEW_SIGNAL_2 : 0|1@0+ (1,0) [0|0] "" XXX
 SG_ NEW_SIGNAL_3 : 1|1@0+ (1,0) [0|0] "" XXX
 SG_ NEW_SIGNAL_4 : 7|6@0+ (1,0) [0|0] "" XXX
 SG_ NEW_SIGNAL_1 : 15|8@0+ (1,0) [0|0] "" XXX
 SG_ NEW_SIGNAL_5 : 22|17@0+ (1,0) [0|0] "" XXX
 SG_ ECON_ON : 23|1@0+ (1,0) [0|0] "" XXX
 SG_ NEW_SIGNAL_6 : 35|6@0+ (1,0) [0|0] "" XXX
 SG_ DRIVE_MODE : 37|2@0+ (1,0) [0|0] "" XXX
 SG_ CHECKSUM : 43|4@0+ (1,0) [0|0] "" XXX
 SG_ COUNTER : 45|2@0+ (1,0) [0|0] "" XXX

BO_ 576 LEFT_LANE_LINE_1: 8 CAM
 SG_ LINE_ANGLE : 7|12@0+ (0.0005,-1.024) [0|0] "" XXX
 SG_ FRAME_INDEX : 8|4@1+ (1,0) [0|0] "" XXX
 SG_ LINE_OFFSET : 23|12@0+ (0.004,-8.192) [0|0] "" XXX
 SG_ LINE_DISTANCE_VISIBLE : 39|9@0+ (1,0) [0|0] "" XXX
 SG_ LINE_PROBABILITY : 46|6@0+ (0.015625,0) [0|0] "" XXX
 SG_ CHECKSUM : 59|4@0+ (1,0) [0|0] "" XXX
 SG_ COUNTER : 61|2@0+ (1,0) [0|0] "" XXX

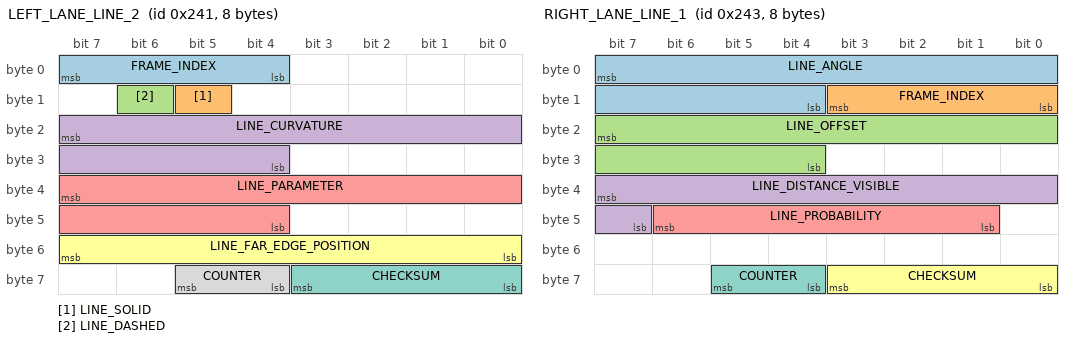
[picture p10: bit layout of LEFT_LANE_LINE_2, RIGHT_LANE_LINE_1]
BO_ 577 LEFT_LANE_LINE_2: 8 CAM
 SG_ FRAME_INDEX : 7|4@0+ (1,0) [0|0] "" XXX
 SG_ LINE_SOLID : 13|1@0+ (1,0) [0|0] "" XXX
 SG_ LINE_DASHED : 14|1@0+ (1,0) [0|0] "" XXX
 SG_ LINE_CURVATURE : 23|12@0+ (1e-05,-0.02048) [0|0] "" XXX
 SG_ LINE_PARAMETER : 39|12@0+ (1,0) [0|0] "" XXX
 SG_ LINE_FAR_EDGE_POSITION : 55|8@0+ (1,-128) [0|0] "" XXX
 SG_ CHECKSUM : 59|4@0+ (1,0) [0|0] "" XXX
 SG_ COUNTER : 61|2@0+ (1,0) [0|0] "" XXX

BO_ 579 RIGHT_LANE_LINE_1: 8 CAM
 SG_ LINE_ANGLE : 7|12@0+ (0.0005,-1.024) [0|0] "" XXX
 SG_ FRAME_INDEX : 8|4@1+ (1,0) [0|0] "" XXX
 SG_ LINE_OFFSET : 23|12@0+ (0.004,-8.192) [0|0] "" XXX
 SG_ LINE_DISTANCE_VISIBLE : 39|9@0+ (1,0) [0|0] "" XXX
 SG_ LINE_PROBABILITY : 46|6@0+ (0.015625,0) [0|0] "" XXX
 SG_ CHECKSUM : 59|4@0+ (1,0) [0|0] "" XXX
 SG_ COUNTER : 61|2@0+ (1,0) [0|0] "" XXX

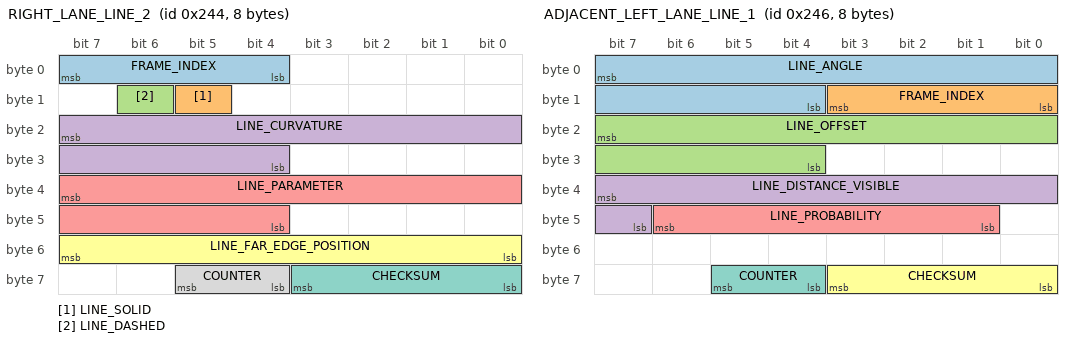
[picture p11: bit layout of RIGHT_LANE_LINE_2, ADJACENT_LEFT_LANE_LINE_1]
BO_ 580 RIGHT_LANE_LINE_2: 8 CAM
 SG_ FRAME_INDEX : 7|4@0+ (1,0) [0|0] "" XXX
 SG_ LINE_SOLID : 13|1@0+ (1,0) [0|0] "" XXX
 SG_ LINE_DASHED : 14|1@0+ (1,0) [0|0] "" XXX
 SG_ LINE_CURVATURE : 23|12@0+ (1e-05,-0.02048) [0|0] "" XXX
 SG_ LINE_PARAMETER : 39|12@0+ (1,0) [0|0] "" XXX
 SG_ LINE_FAR_EDGE_POSITION : 55|8@0+ (1,-128) [0|0] "" XXX
 SG_ CHECKSUM : 59|4@0+ (1,0) [0|0] "" XXX
 SG_ COUNTER : 61|2@0+ (1,0) [0|0] "" XXX

BO_ 582 ADJACENT_LEFT_LANE_LINE_1: 8 CAM
 SG_ LINE_ANGLE : 7|12@0+ (0.0005,-1.024) [0|0] "" XXX
 SG_ FRAME_INDEX : 8|4@1+ (1,0) [0|0] "" XXX
 SG_ LINE_OFFSET : 23|12@0+ (0.004,-8.192) [0|0] "" XXX
 SG_ LINE_DISTANCE_VISIBLE : 39|9@0+ (1,0) [0|0] "" XXX
 SG_ LINE_PROBABILITY : 46|6@0+ (0.015625,0) [0|0] "" XXX
 SG_ CHECKSUM : 59|4@0+ (1,0) [0|0] "" XXX
 SG_ COUNTER : 61|2@0+ (1,0) [0|0] "" XXX

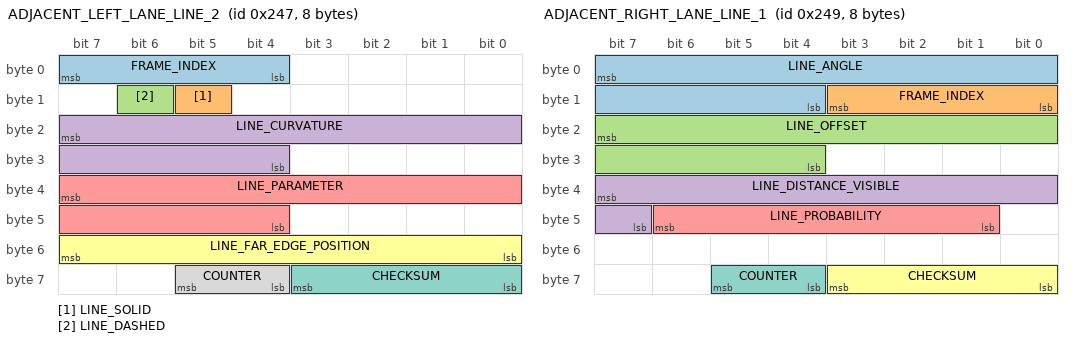
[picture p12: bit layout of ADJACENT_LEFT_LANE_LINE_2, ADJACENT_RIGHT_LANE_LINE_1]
BO_ 583 ADJACENT_LEFT_LANE_LINE_2: 8 CAM
 SG_ FRAME_INDEX : 7|4@0+ (1,0) [0|0] "" XXX
 SG_ LINE_SOLID : 13|1@0+ (1,0) [0|0] "" XXX
 SG_ LINE_DASHED : 14|1@0+ (1,0) [0|0] "" XXX
 SG_ LINE_CURVATURE : 23|12@0+ (1e-05,-0.02048) [0|0] "" XXX
 SG_ LINE_PARAMETER : 39|12@0+ (1,0) [0|0] "" XXX
 SG_ LINE_FAR_EDGE_POSITION : 55|8@0+ (1,-128) [0|0] "" XXX
 SG_ CHECKSUM : 59|4@0+ (1,0) [0|0] "" XXX
 SG_ COUNTER : 61|2@0+ (1,0) [0|0] "" XXX

BO_ 585 ADJACENT_RIGHT_LANE_LINE_1: 8 CAM
 SG_ LINE_ANGLE : 7|12@0+ (0.0005,-1.024) [0|0] "" XXX
 SG_ FRAME_INDEX : 8|4@1+ (1,0) [0|0] "" XXX
 SG_ LINE_OFFSET : 23|12@0+ (0.004,-8.192) [0|0] "" XXX
 SG_ LINE_DISTANCE_VISIBLE : 39|9@0+ (1,0) [0|0] "" XXX
 SG_ LINE_PROBABILITY : 46|6@0+ (0.015625,0) [0|0] "" XXX
 SG_ CHECKSUM : 59|4@0+ (1,0) [0|0] "" XXX
 SG_ COUNTER : 61|2@0+ (1,0) [0|0] "" XXX

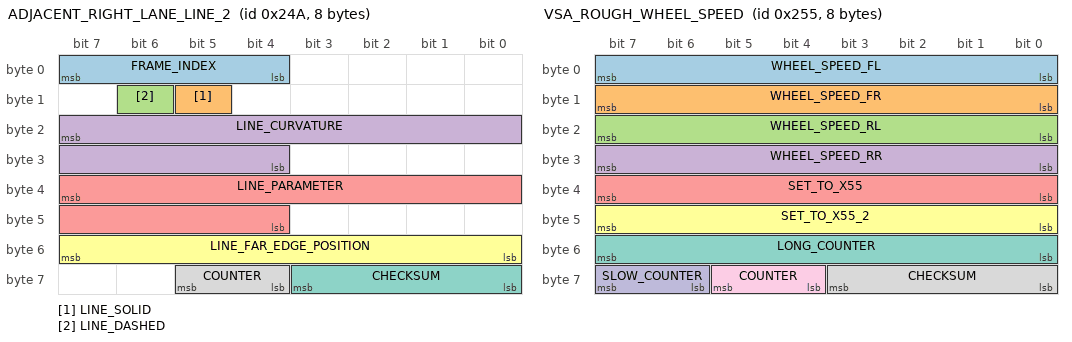
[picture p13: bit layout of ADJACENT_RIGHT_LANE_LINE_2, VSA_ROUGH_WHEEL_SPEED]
BO_ 586 ADJACENT_RIGHT_LANE_LINE_2: 8 CAM
 SG_ FRAME_INDEX : 7|4@0+ (1,0) [0|0] "" XXX
 SG_ LINE_SOLID : 13|1@0+ (1,0) [0|0] "" XXX
 SG_ LINE_DASHED : 14|1@0+ (1,0) [0|0] "" XXX
 SG_ LINE_CURVATURE : 23|12@0+ (1e-05,-0.02048) [0|0] "" XXX
 SG_ LINE_PARAMETER : 39|12@0+ (1,0) [0|0] "" XXX
 SG_ LINE_FAR_EDGE_POSITION : 55|8@0+ (1,-128) [0|0] "" XXX
 SG_ CHECKSUM : 59|4@0+ (1,0) [0|0] "" XXX
 SG_ COUNTER : 61|2@0+ (1,0) [0|0] "" XXX

BO_ 597 VSA_ROUGH_WHEEL_SPEED: 8 VSA
 SG_ WHEEL_SPEED_FL : 7|8@0+ (1,0) [0|0] "" XXX
 SG_ WHEEL_SPEED_FR : 15|8@0+ (1,0) [0|0] "" XXX
 SG_ WHEEL_SPEED_RL : 23|8@0+ (1,0) [0|0] "" XXX
 SG_ WHEEL_SPEED_RR : 31|8@0+ (1,0) [0|0] "" XXX
 SG_ SET_TO_X55 : 39|8@0+ (1,0) [0|0] "" XXX
 SG_ SET_TO_X55_2 : 47|8@0+ (1,0) [0|0] "" XXX
 SG_ LONG_COUNTER : 55|8@0+ (1,0) [0|0] "" XXX
 SG_ CHECKSUM : 59|4@0+ (1,0) [0|0] "" XXX
 SG_ COUNTER : 61|2@0+ (1,0) [0|0] "" XXX
 SG_ SLOW_COUNTER : 63|2@0+ (1,0) [0|0] "" XXX

BO_ 661 CRV_IDK_295: 4 XXX
 SG_ CHECKSUM : 27|4@0+ (1,0) [0|0] "" XXX
 SG_ COUNTER : 29|2@0+ (1,0) [0|0] "" XXX

BO_ 662 METER_SCM_BUTTONS: 4 METER
 SG_ NEW_SIGNAL_2 : 1|20@0+ (1,0) [0|0] "" XXX
 SG_ CRUISE_SETTING : 3|2@0+ (1,0) [0|0] "" XXX
 SG_ NEW_SIGNAL_1 : 4|1@0+ (1,0) [0|0] "" XXX
 SG_ CRUISE_BUTTONS : 7|3@0+ (1,0) [0|0] "" XXX
 SG_ CHECKSUM : 27|4@0+ (1,0) [0|0] "" XXX
 SG_ COUNTER : 29|2@0+ (1,0) [0|0] "" XXX

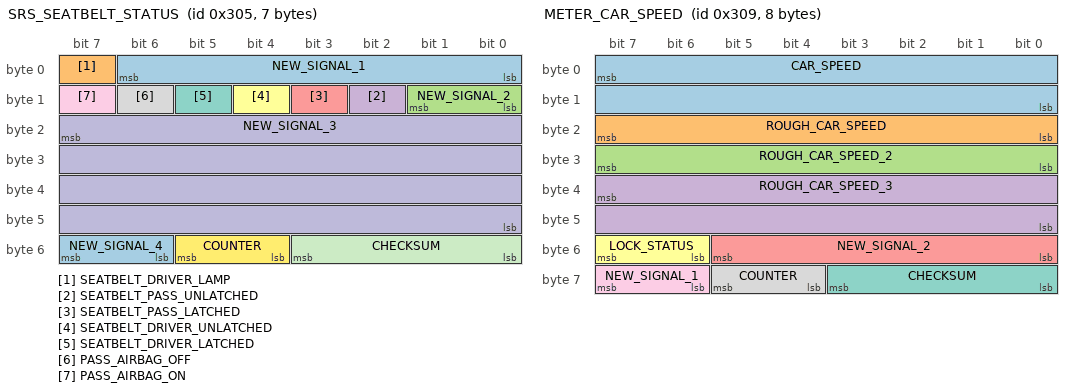
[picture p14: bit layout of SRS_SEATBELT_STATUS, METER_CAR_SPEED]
BO_ 773 SRS_SEATBELT_STATUS: 7 SRS
 SG_ NEW_SIGNAL_1 : 6|7@0+ (1,0) [0|0] "" XXX
 SG_ SEATBELT_DRIVER_LAMP : 7|1@0+ (1,0) [0|0] "" XXX
 SG_ NEW_SIGNAL_2 : 9|2@0+ (1,0) [0|0] "" XXX
 SG_ SEATBELT_PASS_UNLATCHED : 10|1@0+ (1,0) [0|0] "" XXX
 SG_ SEATBELT_PASS_LATCHED : 11|1@0+ (1,0) [0|0] "" XXX
 SG_ SEATBELT_DRIVER_UNLATCHED : 12|1@0+ (1,0) [0|0] "" XXX
 SG_ SEATBELT_DRIVER_LATCHED : 13|1@0+ (1,0) [0|0] "" XXX
 SG_ PASS_AIRBAG_OFF : 14|1@0+ (1,0) [0|0] "" XXX
 SG_ PASS_AIRBAG_ON : 15|1@0+ (1,0) [0|0] "" XXX
 SG_ NEW_SIGNAL_3 : 23|32@0+ (1,0) [0|0] "" XXX
 SG_ CHECKSUM : 51|4@0+ (1,0) [0|0] "" XXX
 SG_ COUNTER : 53|2@0+ (1,0) [0|0] "" XXX
 SG_ NEW_SIGNAL_4 : 55|2@0+ (1,0) [0|0] "" XXX

BO_ 777 METER_CAR_SPEED: 8 METER
 SG_ CAR_SPEED : 7|16@0+ (0.01,0) [0|0] "" XXX
 SG_ ROUGH_CAR_SPEED : 23|8@0+ (1,0) [0|0] "" XXX
 SG_ ROUGH_CAR_SPEED_2 : 31|8@0+ (1,0) [0|0] "" XXX
 SG_ ROUGH_CAR_SPEED_3 : 39|16@0+ (0.01,0) [0|0] "" XXX
 SG_ NEW_SIGNAL_2 : 53|6@0+ (1,0) [0|0] "" XXX
 SG_ LOCK_STATUS : 55|2@0+ (1,0) [0|0] "" XXX
 SG_ CHECKSUM : 59|4@0+ (1,0) [0|0] "" XXX
 SG_ COUNTER : 61|2@0+ (1,0) [0|0] "" XXX
 SG_ NEW_SIGNAL_1 : 63|2@0+ (1,0) [0|0] "" XXX

BO_ 780 RADAR_ACC_HUD: 8 RADAR
 SG_ ZEROS_BOH : 7|24@0+ (0.002759506,0) [0|0] "" XXX
 SG_ CRUISE_SPEED : 31|8@0+ (1,0) [0|0] "" XXX
 SG_ ENABLE_MINI_CAR : 32|1@0+ (1,0) [0|0] "" XXX
 SG_ RADAR_OBSTRUCTED : 33|1@0+ (1,0) [0|0] "" XXX
 SG_ FCM_PROBLEM : 34|1@0+ (1,0) [0|0] "" XXX
 SG_ FCM_OFF : 35|1@0+ (1,0) [0|0] "" XXX
 SG_ FCM_OFF_2 : 36|1@0+ (1,0) [0|0] "" XXX
 SG_ ACC_PROBLEM : 37|1@0+ (1,0) [0|0] "" XXX
 SG_ BOH : 38|1@0+ (1,0) [0|0] "" XXX
 SG_ DTC_MODE : 39|1@0+ (1,0) [0|0] "" XXX
 SG_ CRUISE_CONTROL_LABEL : 40|1@0+ (1,0) [0|0] "" XXX
 SG_ BOH_5 : 41|1@0+ (1,0) [0|0] "" XXX
 SG_ BOH_4 : 42|1@0+ (1,0) [0|0] "" XXX
 SG_ BOH_3 : 43|1@0+ (1,0) [0|0] "" XXX
 SG_ HUD_LEAD : 45|2@0+ (1,0) [0|0] "" XXX
 SG_ HUD_DISTANCE : 47|2@0+ (1,0) [0|0] "" XXX
 SG_ BOH_6 : 51|4@0+ (1,0) [0|0] "" XXX
 SG_ ACC_ON : 52|1@0+ (1,0) [0|0] "" XXX
 SG_ NEW_SIGNAL_1 : 53|1@0+ (1,0) [0|0] "" XXX
 SG_ IMPERIAL_UNIT : 54|1@0+ (1,0) [0|0] "" XXX
 SG_ SET_TO_X1 : 55|1@0+ (1,0) [0|0] "" XXX
 SG_ CHECKSUM : 59|4@0+ (1,0) [0|0] "" XXX
 SG_ COUNTER : 61|2@0+ (1,0) [0|0] "" XXX
 SG_ ACC_PROBLEM_MINI_ICON : 62|1@0+ (1,0) [0|0] "" XXX
 SG_ FCM_OFF_MINI_ICON : 63|1@0+ (1,0) [0|0] "" XXX

BO_ 795 VSA_GATEWAYFORWARD_31B: 8 VSA
 SG_ NEW_SIGNAL_5 : 7|8@0+ (1,0) [0|0] "" XXX
 SG_ NEW_SIGNAL_6 : 15|8@0+ (1,0) [0|0] "" XXX
 SG_ NEW_SIGNAL_3 : 23|40@0+ (1,0) [0|0] "" XXX
 SG_ CHECKSUM : 59|4@0+ (1,0) [0|0] "" XXX
 SG_ COUNTER : 61|2@0+ (1,0) [0|0] "" XXX
 SG_ NEW_SIGNAL_4 : 63|2@0+ (1,0) [0|0] "" XXX

BO_ 800 PCM_GATEWAYFORWARD_320: 8 PCM
 SG_ NEW_SIGNAL_1 : 7|56@0+ (1,0) [0|0] "" XXX
 SG_ CHECKSUM : 59|4@0+ (1,0) [0|0] "" XXX
 SG_ COUNTER : 61|2@0+ (1,0) [0|0] "" XXX
 SG_ NEW_SIGNAL_2 : 63|2@0+ (1,0) [0|0] "" XXX

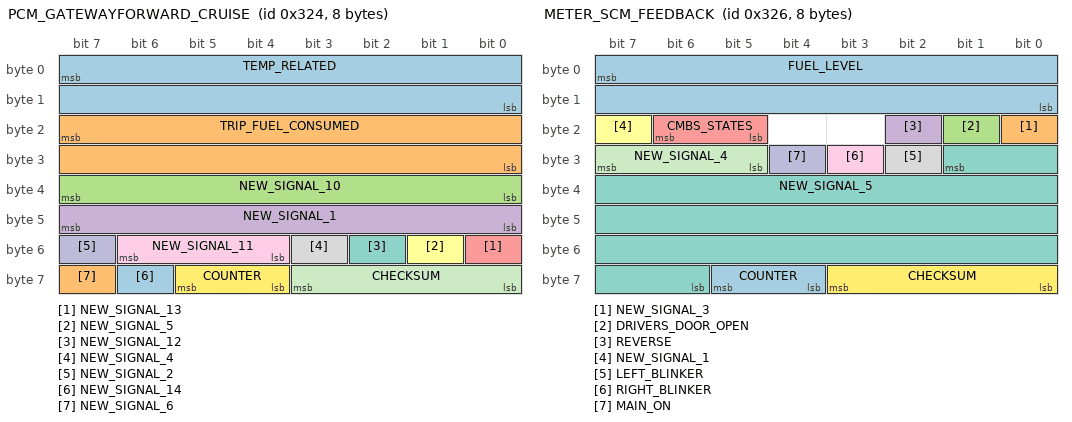
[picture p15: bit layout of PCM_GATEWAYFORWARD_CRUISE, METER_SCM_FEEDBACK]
BO_ 804 PCM_GATEWAYFORWARD_CRUISE: 8 PCM
 SG_ TEMP_RELATED : 7|16@0+ (0.006,0) [0|0] "" XXX
 SG_ TRIP_FUEL_CONSUMED : 23|16@0+ (1,0) [0|0] "" XXX
 SG_ NEW_SIGNAL_10 : 39|8@0+ (1,0) [0|0] "" XXX
 SG_ NEW_SIGNAL_1 : 47|8@0+ (1,0) [0|0] "" XXX
 SG_ NEW_SIGNAL_13 : 48|1@0+ (1,0) [0|0] "" XXX
 SG_ NEW_SIGNAL_5 : 49|1@0+ (1,0) [0|0] "" XXX
 SG_ NEW_SIGNAL_12 : 50|1@0+ (1,0) [0|0] "" XXX
 SG_ NEW_SIGNAL_4 : 51|1@0+ (1,0) [0|0] "" XXX
 SG_ NEW_SIGNAL_11 : 54|3@0+ (1,0) [0|0] "" XXX
 SG_ NEW_SIGNAL_2 : 55|1@0+ (1,0) [0|0] "" XXX
 SG_ CHECKSUM : 59|4@0+ (1,0) [0|0] "" XXX
 SG_ COUNTER : 61|2@0+ (1,0) [0|0] "" XXX
 SG_ NEW_SIGNAL_14 : 62|1@0+ (1,0) [0|0] "" XXX
 SG_ NEW_SIGNAL_6 : 63|1@0+ (1,0) [0|0] "" XXX

BO_ 806 METER_SCM_FEEDBACK: 8 METER
 SG_ FUEL_LEVEL : 7|16@0+ (1,0) [0|0] "" XXX
 SG_ NEW_SIGNAL_3 : 16|1@0+ (1,0) [0|0] "" XXX
 SG_ DRIVERS_DOOR_OPEN : 17|1@0+ (1,0) [0|0] "" XXX
 SG_ REVERSE : 18|1@0+ (1,0) [0|1] "" XXX
 SG_ CMBS_STATES : 22|2@0+ (1,0) [0|0] "" XXX
 SG_ NEW_SIGNAL_1 : 23|1@0+ (1,0) [0|0] "" XXX
 SG_ NEW_SIGNAL_5 : 25|28@0+ (1,0) [0|0] "" XXX
 SG_ LEFT_BLINKER : 26|1@0+ (1,0) [0|0] "" XXX
 SG_ RIGHT_BLINKER : 27|1@0+ (1,0) [0|0] "" XXX
 SG_ MAIN_ON : 28|1@0+ (1,0) [0|0] "" XXX
 SG_ NEW_SIGNAL_4 : 31|3@0+ (1,0) [0|0] "" XXX
 SG_ CHECKSUM : 59|4@0+ (1,0) [0|0] "" XXX
 SG_ COUNTER : 61|2@0+ (1,0) [0|0] "" XXX

BO_ 808 PCM_GATEWAYFORWARD_328: 8 PCM
 SG_ NEW_SIGNAL_2 : 7|40@0+ (1,0) [0|0] "" XXX
 SG_ NEW_SIGNAL_3 : 45|15@0+ (1,0) [0|0] "" XXX
 SG_ NEW_SIGNAL_1 : 47|2@0+ (1,0) [0|0] "" XXX
 SG_ CHECKSUM : 59|4@0+ (1,0) [0|0] "" XXX
 SG_ COUNTER : 61|2@0+ (1,0) [0|0] "" XXX
 SG_ NEW_SIGNAL_4 : 62|1@0+ (1,0) [0|0] "" XXX

BO_ 814 CRV_IDK_32E: 4 XXX
 SG_ NEW_SIGNAL_1 : 7|8@0+ (1,0) [0|0] "" XXX
 SG_ NEW_SIGNAL_2 : 15|8@0+ (1,0) [0|0] "" XXX
 SG_ NEW_SIGNAL_3 : 23|8@0+ (1,0) [0|0] "" XXX
 SG_ CHECKSUM : 27|4@0+ (1,0) [0|0] "" XXX
 SG_ COUNTER : 29|2@0+ (1,0) [0|0] "" XXX

BO_ 815 OBD2_PCM_32F: 8 PCM
 SG_ NEW_SIGNAL_1 : 7|56@0+ (1,0) [0|0] "" XXX
 SG_ CHECKSUM : 59|4@0+ (1,0) [0|0] "" XXX
 SG_ COUNTER : 61|2@0+ (1,0) [0|0] "" XXX
 SG_ NEW_SIGNAL_2 : 63|2@0+ (1,0) [0|0] "" XXX

BO_ 817 CRV_IDK_331: 4 XXX
 SG_ NEW_SIGNAL_1 : 7|8@0+ (1,0) [0|0] "" XXX
 SG_ CHECKSUM : 27|4@0+ (1,0) [0|0] "" XXX
 SG_ COUNTER : 29|2@0+ (1,0) [0|0] "" XXX

BO_ 825 OBD2_PCM_339: 4 PCM
 SG_ NEW_SIGNAL_1 : 7|8@0+ (1,0) [0|0] "" XXX
 SG_ NEW_SIGNAL_2 : 15|8@0+ (1,0) [0|0] "" XXX
 SG_ NEW_SIGNAL_3 : 23|8@0+ (1,0) [0|0] "" XXX
 SG_ CHECKSUM : 27|4@0+ (1,0) [0|0] "" XXX
 SG_ COUNTER : 29|2@0+ (1,0) [0|0] "" XXX
 SG_ NEW_SIGNAL_4 : 31|2@0+ (1,0) [0|0] "" XXX

BO_ 829 RADAR_LKAS_HUD: 5 RADAR
 SG_ ENABLED : 0|1@0+ (1,0) [0|0] "" XXX
 SG_ LKAS_PROBLEM : 1|1@0+ (1,0) [0|0] "" XXX
 SG_ NEW_SIGNAL_6 : 3|2@0+ (1,0) [0|0] "" XXX
 SG_ LKAS_NOW_AVAILABLE : 4|1@0+ (1,0) [0|0] "" XXX
 SG_ NEW_SIGNAL_5 : 5|1@0+ (1,0) [0|0] "" XXX
 SG_ RECENT_STATE_CHANGE : 6|1@0+ (1,0) [0|0] "" XXX
 SG_ CAM_TEMP_HIGH : 7|1@0+ (1,0) [0|0] "" XXX
 SG_ STEERING_REQUIRED : 8|1@0+ (1,0) [0|0] "" XXX
 SG_ LANE_DEPARTURE_ALERT : 9|1@0+ (1,0) [0|0] "" XXX
 SG_ SOLID_LANES : 10|1@0+ (1,0) [0|0] "" XXX
 SG_ LKAS_OFF : 11|1@0+ (1,0) [0|0] "" XXX
 SG_ LKAS_PROBLEM_MINI_ICON : 12|1@0+ (1,0) [0|0] "" XXX
 SG_ DTC : 13|1@0+ (1,0) [0|0] "" XXX
 SG_ DASHED_LANES : 14|1@0+ (1,0) [0|0] "" XXX
 SG_ CAM_TEMP_TOO_HOT : 15|1@0+ (1,0) [0|0] "" XXX
 SG_ BEEP : 17|2@0+ (1,0) [0|0] "" XXX
 SG_ DOUBLE_BEEP : 18|1@0+ (1,0) [0|0] "" XXX
 SG_ NEW_SIGNAL_7 : 19|1@0+ (1,0) [0|0] "" XXX
 SG_ RDM_ON : 20|1@0+ (1,0) [0|0] "" XXX
 SG_ RDM_PROBLEM : 21|1@0+ (1,0) [0|0] "" XXX
 SG_ LDW_ICON : 22|1@0+ (1,0) [0|0] "" XXX
 SG_ NEW_SIGNAL_3 : 23|1@0+ (1,0) [0|0] "" XXX
 SG_ RDM_SETTING : 25|2@0+ (1,0) [0|0] "" XXX
 SG_ CLEAN_WINDSHIELD : 26|1@0+ (1,0) [0|0] "" XXX
 SG_ RDM_OFF : 27|1@0+ (1,0) [0|0] "" XXX
 SG_ RDM_ON_2 : 28|1@0+ (1,0) [0|0] "" XXX
 SG_ NEW_SIGNAL_4 : 29|1@0+ (1,0) [0|0] "" XXX
 SG_ LKAS_BEEP_OFF : 30|1@0+ (1,0) [0|0] "" XXX
 SG_ NEW_SIGNAL_2 : 31|1@0+ (1,0) [0|0] "" XXX
 SG_ CHECKSUM : 35|4@0+ (1,0) [0|0] "" XXX
 SG_ COUNTER : 37|2@0+ (1,0) [0|0] "" XXX
 SG_ NEW_SIGNAL_1 : 39|2@0+ (1,0) [0|0] "" XXX

BO_ 846 OBD2_PCM_34E: 8 PCM
 SG_ NEW_SIGNAL_1 : 7|8@0+ (1,0) [0|0] "" XXX
 SG_ NEW_SIGNAL_2 : 15|8@0+ (1,0) [0|0] "" XXX
 SG_ NEW_SIGNAL_3 : 23|42@0+ (1,0) [0|0] "" XXX
 SG_ NEW_SIGNAL_5 : 59|4@0+ (1,0) [0|0] "" XXX
 SG_ NEW_SIGNAL_4 : 61|2@0+ (1,0) [0|0] "" XXX

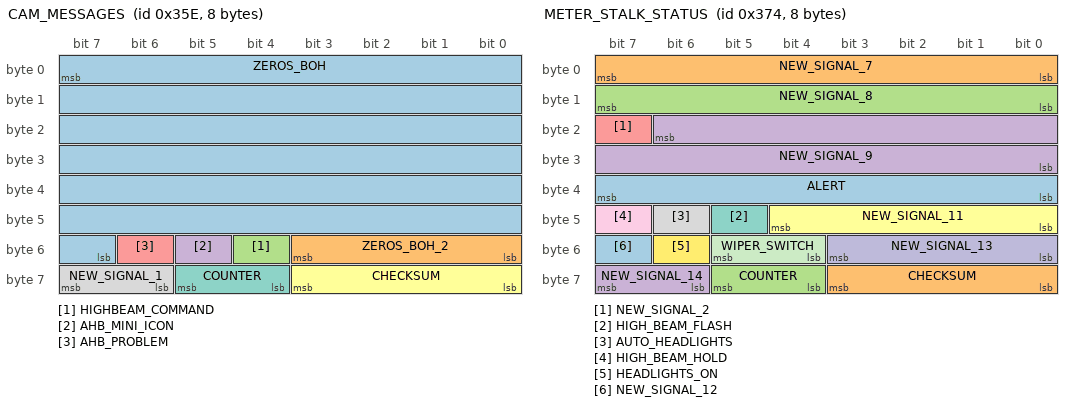
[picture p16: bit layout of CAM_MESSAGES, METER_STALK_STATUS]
BO_ 862 CAM_MESSAGES: 8 CAM
 SG_ ZEROS_BOH : 7|49@0+ (1,0) [0|0] "" XXX
 SG_ ZEROS_BOH_2 : 51|4@0+ (1,0) [0|0] "" XXX
 SG_ HIGHBEAM_COMMAND : 52|1@0+ (1,0) [0|0] "" XXX
 SG_ AHB_MINI_ICON : 53|1@0+ (1,0) [0|0] "" XXX
 SG_ AHB_PROBLEM : 54|1@0+ (1,0) [0|1] "" XXX
 SG_ CHECKSUM : 59|4@0+ (1,0) [0|0] "" XXX
 SG_ COUNTER : 61|2@0+ (1,0) [0|0] "" XXX
 SG_ NEW_SIGNAL_1 : 63|2@0+ (1,0) [0|0] "" XXX

BO_ 871 NEW_MSG_1: 8 XXX

BO_ 881 OBD2_METER_371: 8 METER
 SG_ NEW_SIGNAL_1 : 7|58@0+ (1,0) [0|0] "" XXX
 SG_ CHECKSUM : 59|4@0+ (1,0) [0|0] "" XXX
 SG_ COUNTER : 61|2@0+ (1,0) [0|0] "" XXX

BO_ 882 OBD2_METER_372: 4 METER
 SG_ NEW_SIGNAL_1 : 7|8@0+ (1,0) [0|0] "" XXX
 SG_ NEW_SIGNAL_2 : 15|18@0+ (1,0) [0|0] "" XXX
 SG_ CHECKSUM : 27|4@0+ (1,0) [0|0] "" XXX
 SG_ COUNTER : 29|2@0+ (1,0) [0|0] "" XXX

BO_ 884 METER_STALK_STATUS: 8 METER
 SG_ ALERT M : 39|8@0+ (1,0) [0|255] "" XXX
 SG_ NEW_SIGNAL_7 : 7|8@0+ (1,0) [0|0] "" XXX
 SG_ NEW_SIGNAL_8 : 15|8@0+ (1,0) [0|0] "" XXX
 SG_ NEW_SIGNAL_9 : 22|15@0+ (1,0) [0|0] "" XXX
 SG_ NEW_SIGNAL_2 : 23|1@0+ (1,0) [0|0] "" XXX
 SG_ NEW_SIGNAL_11 : 44|5@0+ (1,0) [0|0] "" XXX
 SG_ HIGH_BEAM_FLASH : 45|1@0+ (1,0) [0|0] "" XXX
 SG_ AUTO_HEADLIGHTS : 46|1@0+ (1,0) [0|0] "" XXX
 SG_ HIGH_BEAM_HOLD : 47|1@0+ (1,0) [0|0] "" XXX
 SG_ NEW_SIGNAL_13 : 51|4@0+ (1,0) [0|0] "" XXX
 SG_ WIPER_SWITCH : 53|2@0+ (1,0) [0|0] "" XXX
 SG_ HEADLIGHTS_ON : 54|1@0+ (1,0) [0|0] "" XXX
 SG_ NEW_SIGNAL_12 : 55|1@0+ (1,0) [0|0] "" XXX
 SG_ CHECKSUM : 59|4@0+ (1,0) [0|0] "" XXX
 SG_ COUNTER : 61|2@0+ (1,0) [0|0] "" XXX
 SG_ NEW_SIGNAL_14 : 63|2@0+ (1,0) [0|0] "" XXX

BO_ 888 OBD2_METER_378: 8 METER
 SG_ NEW_SIGNAL_1 : 7|32@0+ (1,0) [0|0] "" XXX
 SG_ NEW_SIGNAL_2 : 39|8@0+ (1,0) [0|0] "" XXX
 SG_ NEW_SIGNAL_3 : 47|8@0+ (1,0) [0|0] "" XXX
 SG_ NEW_SIGNAL_4 : 55|8@0+ (1,0) [0|0] "" XXX
 SG_ CHECKSUM : 59|4@0+ (1,0) [0|0] "" XXX
 SG_ COUNTER : 61|2@0+ (1,0) [0|0] "" XXX
 SG_ NEW_SIGNAL_5 : 63|2@0+ (1,0) [0|0] "" XXX

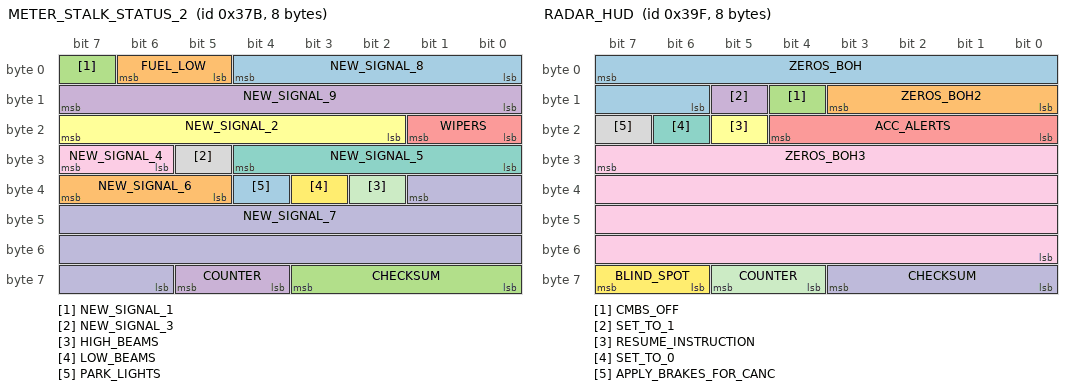
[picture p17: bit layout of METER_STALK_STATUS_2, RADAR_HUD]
BO_ 891 METER_STALK_STATUS_2: 8 METER
 SG_ NEW_SIGNAL_8 : 4|5@0+ (1,0) [0|31] "" XXX
 SG_ FUEL_LOW : 6|2@0+ (1,0) [0|0] "" XXX
 SG_ NEW_SIGNAL_1 : 7|1@0+ (1,0) [0|1] "" XXX
 SG_ NEW_SIGNAL_9 : 15|8@0+ (1,0) [0|255] "" XXX
 SG_ WIPERS : 17|2@0+ (1,0) [0|0] "" XXX
 SG_ NEW_SIGNAL_2 : 23|6@0+ (1,0) [0|0] "" XXX
 SG_ NEW_SIGNAL_5 : 28|5@0+ (1,0) [0|0] "" XXX
 SG_ NEW_SIGNAL_3 : 29|1@0+ (1,0) [0|0] "" XXX
 SG_ NEW_SIGNAL_4 : 31|2@0+ (1,0) [0|0] "" XXX
 SG_ NEW_SIGNAL_7 : 33|20@0+ (1,0) [0|0] "" XXX
 SG_ HIGH_BEAMS : 34|1@0+ (1,0) [0|0] "" XXX
 SG_ LOW_BEAMS : 35|1@0+ (1,0) [0|0] "" XXX
 SG_ PARK_LIGHTS : 36|1@0+ (1,0) [0|0] "" XXX
 SG_ NEW_SIGNAL_6 : 39|3@0+ (1,0) [0|0] "" XXX
 SG_ CHECKSUM : 59|4@0+ (1,0) [0|0] "" XXX
 SG_ COUNTER : 61|2@0+ (1,0) [0|0] "" XXX

BO_ 892 PCM_GATEWAYFORWARD_CRUISE_PARAMS: 8 PCM
 SG_ NEW_SIGNAL_1 : 7|8@0- (1,0) [0|0] "" XXX
 SG_ NEW_SIGNAL_3 : 15|8@0+ (1,0) [0|0] "" XXX
 SG_ NEW_SIGNAL_2 : 23|8@0+ (1,0) [0|0] "" XXX
 SG_ CRUISE_SPEED_OFFSET : 31|8@0- (0.1,0) [0|0] "" XXX
 SG_ NEW_SIGNAL_4 : 39|24@0+ (1,0) [0|0] "" XXX
 SG_ CHECKSUM : 59|4@0+ (1,0) [0|0] "" XXX
 SG_ COUNTER : 61|2@0+ (1,0) [0|0] "" XXX
 SG_ NEW_SIGNAL_5 : 63|2@0+ (1,0) [0|0] "" XXX

BO_ 918 OBD2_METER_396: 7 METER
 SG_ NEW_SIGNAL_1 : 7|24@0+ (1,0) [0|0] "" XXX
 SG_ NEW_SIGNAL_2 : 31|8@0+ (1,0) [0|0] "" XXX
 SG_ NEW_SIGNAL_3 : 39|18@0+ (1,0) [0|0] "" XXX
 SG_ CHECKSUM : 51|4@0+ (1,0) [0|0] "" XXX
 SG_ COUNTER : 53|2@0+ (1,0) [0|0] "" XXX

BO_ 927 RADAR_HUD: 8 RADAR
 SG_ ZEROS_BOH : 7|10@0+ (1,0) [0|0] "" XXX
 SG_ ZEROS_BOH2 : 11|4@0+ (1,0) [0|0] "" XXX
 SG_ CMBS_OFF : 12|1@0+ (1,0) [0|0] "" XXX
 SG_ SET_TO_1 : 13|1@0+ (1,0) [0|0] "" XXX
 SG_ ACC_ALERTS : 20|5@0+ (1,0) [0|0] "" XXX
 SG_ RESUME_INSTRUCTION : 21|1@0+ (1,0) [0|0] "" XXX
 SG_ SET_TO_0 : 22|1@0+ (1,0) [0|0] "" XXX
 SG_ APPLY_BRAKES_FOR_CANC : 23|1@0+ (1,0) [0|0] "" XXX
 SG_ ZEROS_BOH3 : 31|32@0+ (1,0) [0|0] "" XXX
 SG_ CHECKSUM : 59|4@0+ (1,0) [0|0] "" XXX
 SG_ COUNTER : 61|2@0+ (1,0) [0|0] "" XXX
 SG_ BLIND_SPOT : 63|2@0+ (1,0) [0|0] "" XXX

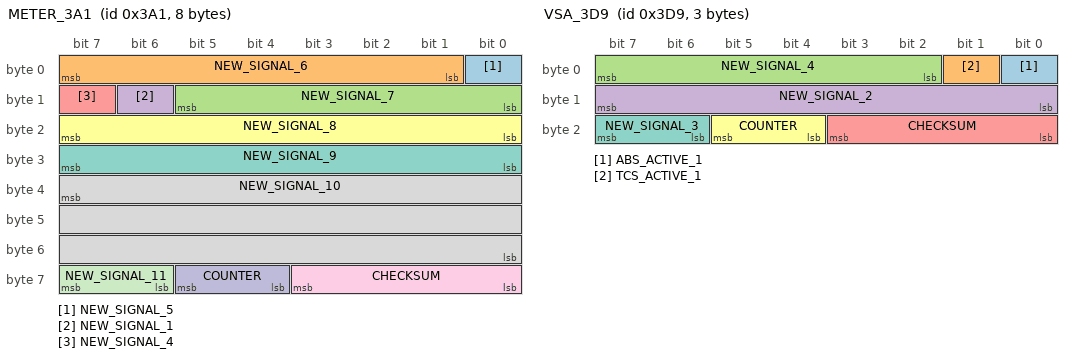
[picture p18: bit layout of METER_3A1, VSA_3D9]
BO_ 929 METER_3A1: 8 METER
 SG_ NEW_SIGNAL_5 : 0|1@0+ (1,0) [0|0] "" XXX
 SG_ NEW_SIGNAL_6 : 7|7@0+ (1,0) [0|0] "" XXX
 SG_ NEW_SIGNAL_7 : 13|6@0+ (1,0) [0|0] "" XXX
 SG_ NEW_SIGNAL_1 : 14|1@0+ (1,0) [0|0] "" XXX
 SG_ NEW_SIGNAL_4 : 15|1@0+ (1,0) [0|0] "" XXX
 SG_ NEW_SIGNAL_8 : 23|8@0+ (1,0) [0|0] "" XXX
 SG_ NEW_SIGNAL_9 : 31|8@0+ (1,0) [0|0] "" XXX
 SG_ NEW_SIGNAL_10 : 39|24@0+ (1,0) [0|0] "" XXX
 SG_ CHECKSUM : 59|4@0+ (1,0) [0|0] "" XXX
 SG_ COUNTER : 61|2@0+ (1,0) [0|0] "" XXX
 SG_ NEW_SIGNAL_11 : 63|2@0+ (1,0) [0|0] "" XXX

BO_ 983 OBD2_PCM_3D7: 8 PCM
 SG_ NEW_SIGNAL_1 : 7|8@0+ (1,0) [0|0] "" XXX
 SG_ NEW_SIGNAL_2 : 15|8@0+ (1,0) [0|0] "" XXX
 SG_ NEW_SIGNAL_3 : 23|8@0+ (1,0) [0|0] "" XXX
 SG_ NEW_SIGNAL_4 : 31|8@0+ (1,0) [0|0] "" XXX
 SG_ NEW_SIGNAL_5 : 39|8@0+ (1,0) [0|0] "" XXX
 SG_ NEW_SIGNAL_6 : 47|8@0+ (1,0) [0|0] "" XXX
 SG_ NEW_SIGNAL_7 : 55|8@0+ (1,0) [0|0] "" XXX
 SG_ COUNT_A : 58|3@0+ (1,0) [0|0] "" XXX
 SG_ COUNT_B : 62|3@0+ (1,0) [0|0] "" XXX

BO_ 985 VSA_3D9: 3 VSA
 SG_ ABS_ACTIVE_1 : 0|1@0+ (1,0) [0|0] "" XXX
 SG_ TCS_ACTIVE_1 : 1|1@0+ (1,0) [0|1] "" XXX
 SG_ NEW_SIGNAL_4 : 7|6@0+ (1,0) [0|63] "" XXX
 SG_ NEW_SIGNAL_2 : 15|8@0+ (1,0) [0|0] "" XXX
 SG_ CHECKSUM : 19|4@0+ (1,0) [0|0] "" XXX
 SG_ COUNTER : 21|2@0+ (1,0) [0|0] "" XXX
 SG_ NEW_SIGNAL_3 : 23|2@0+ (1,0) [0|0] "" XXX

BO_ 1024 PCM_GATEWAYFORWARD_400: 5 PCM
 SG_ NEW_SIGNAL_1 : 7|16@0+ (1,0) [0|0] "" XXX
 SG_ NEW_SIGNAL_5 : 23|8@0+ (1,0) [0|0] "" XXX
 SG_ NEW_SIGNAL_6 : 31|8@0+ (1,0) [0|0] "" XXX
 SG_ CHECKSUM : 35|4@0+ (1,0) [0|0] "" XXX
 SG_ COUNTER : 37|2@0+ (1,0) [0|0] "" XXX
 SG_ NEW_SIGNAL_2 : 39|2@0+ (1,0) [0|0] "" XXX

BO_ 1027 TCM_GATEWAYFORWARD_403: 5 TCM
 SG_ NEW_SIGNAL_3 : 7|8@0+ (1,0) [0|0] "" XXX
 SG_ NEW_SIGNAL_4 : 15|8@0+ (1,0) [0|0] "" XXX
 SG_ NEW_SIGNAL_5 : 23|8@0+ (1,0) [0|0] "" XXX
 SG_ NEW_SIGNAL_6 : 31|8@0+ (1,0) [0|0] "" XXX
 SG_ CHECKSUM : 35|4@0+ (1,0) [0|0] "" XXX
 SG_ COUNTER : 37|2@0+ (1,0) [0|0] "" XXX
 SG_ NEW_SIGNAL_7 : 39|2@0+ (1,0) [0|0] "" XXX

BO_ 1029 METER_DOORS_STATUS: 8 METER
 SG_ NEW_SIGNAL_10 : 1|2@0+ (1,0) [0|3] "" XXX
 SG_ FUEL_LOW : 2|1@0+ (1,0) [0|0] "" XXX
 SG_ NEW_SIGNAL_9 : 7|5@0+ (1,0) [0|31] "" XXX
 SG_ NEW_SIGNAL_2 : 15|8@0+ (1,0) [0|0] "" XXX
 SG_ NEW_SIGNAL_3 : 23|8@0+ (1,0) [0|0] "" XXX
 SG_ NEW_SIGNAL_4 : 31|8@0+ (1,0) [0|0] "" XXX
 SG_ NEW_SIGNAL_5 : 36|5@0+ (1,0) [0|0] "" XXX
 SG_ DOOR_OPEN_FL : 37|1@0+ (1,0) [0|0] "" XXX
 SG_ DOOR_OPEN_FR : 38|1@0+ (1,0) [0|0] "" XXX
 SG_ DOOR_OPEN_RL : 39|1@0+ (1,0) [0|0] "" XXX
 SG_ DOOR_OPEN_RR : 40|1@0+ (1,0) [0|0] "" XXX
 SG_ TRUNK_OPEN : 41|1@0+ (1,0) [0|0] "" XXX
 SG_ NEW_SIGNAL_6 : 47|6@0+ (1,0) [0|0] "" XXX
 SG_ NEW_SIGNAL_7 : 55|8@0+ (1,0) [0|0] "" XXX
 SG_ CHECKSUM : 59|4@0+ (1,0) [0|0] "" XXX
 SG_ COUNTER : 61|2@0+ (1,0) [0|0] "" XXX
 SG_ NEW_SIGNAL_8 : 63|2@0+ (1,0) [0|0] "" XXX

BO_ 1036 PCM_GATEWAYFORWARD_DTC: 8 PCM
 SG_ NEW_SIGNAL_2 : 7|8@0+ (1,0) [0|0] "" XXX
 SG_ NEW_SIGNAL_1 : 15|8@0+ (1,0) [0|0] "" XXX
 SG_ NEW_SIGNAL_3 : 23|8@0+ (1,0) [0|0] "" XXX
 SG_ NEW_SIGNAL_4 : 31|8@0+ (1,0) [0|0] "" XXX
 SG_ NEW_SIGNAL_5 : 39|8@0+ (1,0) [0|0] "" XXX
 SG_ NEW_SIGNAL_6 : 47|8@0+ (1,0) [0|0] "" XXX
 SG_ NEW_SIGNAL_7 : 55|8@0+ (1,0) [0|0] "" XXX
 SG_ CHECKSUM : 59|4@0+ (1,0) [0|0] "" XXX
 SG_ COUNTER : 61|2@0+ (1,0) [0|0] "" XXX
 SG_ NEW_SIGNAL_10 : 63|2@0+ (1,0) [0|0] "" XXX

BO_ 1039 TCM_GATEWAYFORWARD_DTC: 8 TCM
 SG_ NEW_SIGNAL_1 : 7|8@0+ (1,0) [0|0] "" XXX
 SG_ NEW_SIGNAL_2 : 15|8@0+ (1,0) [0|0] "" XXX
 SG_ NEW_SIGNAL_3 : 23|8@0+ (1,0) [0|0] "" XXX
 SG_ NEW_SIGNAL_4 : 31|8@0+ (1,0) [0|0] "" XXX
 SG_ NEW_SIGNAL_5 : 39|8@0+ (1,0) [0|0] "" XXX
 SG_ NEW_SIGNAL_6 : 47|8@0+ (1,0) [0|0] "" XXX
 SG_ NEW_SIGNAL_7 : 55|8@0+ (1,0) [0|0] "" XXX
 SG_ CHECKSUM : 59|4@0+ (1,0) [0|0] "" XXX
 SG_ COUNTER : 61|2@0+ (1,0) [0|0] "" XXX
 SG_ NEW_SIGNAL_8 : 63|2@0+ (1,0) [0|0] "" XXX

BO_ 1040 RADAR_FIRMWARE_ID: 6 RADAR
 SG_ VEH_CODE_ASCII_A : 7|8@0+ (1,0) [0|0] "" XXX
 SG_ VEH_CODE_ASCII_B : 15|8@0+ (1,0) [0|0] "" XXX
 SG_ VEH_CODE_ASCII_C : 23|8@0+ (1,0) [0|0] "" XXX
 SG_ VEH_CODE_REV_ASCII_A : 31|8@0+ (1,0) [0|0] "" XXX
 SG_ VEH_CODE_REV_DECIMAL_BCD : 39|8@0+ (1,0) [0|0] "" XXX
 SG_ CHECKSUM : 43|4@0+ (1,0) [0|0] "" XXX
 SG_ COUNTER : 45|2@0+ (1,0) [0|0] "" XXX

BO_ 1064 OBD2_METER_428: 7 METER
 SG_ NEW_SIGNAL_1 : 7|8@0+ (1,0) [0|0] "" XXX
 SG_ NEW_SIGNAL_2 : 15|8@0+ (1,0) [0|0] "" XXX
 SG_ NEW_SIGNAL_3 : 23|8@0+ (1,0) [0|0] "" XXX
 SG_ NEW_SIGNAL_4 : 31|8@0+ (1,0) [0|0] "" XXX
 SG_ NEW_SIGNAL_5 : 39|8@0+ (1,0) [0|0] "" XXX
 SG_ NEW_SIGNAL_6 : 47|8@0+ (1,0) [0|0] "" XXX
 SG_ CHECKSUM : 51|4@0+ (1,0) [0|0] "" XXX
 SG_ COUNTER : 53|2@0+ (1,0) [0|0] "" XXX
 SG_ NEW_SIGNAL_7 : 55|2@0+ (1,0) [0|0] "" XXX

BO_ 1092 OBD2_METER_444: 1 METER
 SG_ CHECKSUM : 3|4@0+ (1,0) [0|0] "" XXX
 SG_ COUNTER : 5|2@0+ (1,0) [0|0] "" XXX
 SG_ NEW_SIGNAL_1 : 7|2@0+ (1,0) [0|0] "" XXX

BO_ 1093 CRV_IDK_445: 4 XXX
 SG_ NEW_SIGNAL_1 : 7|8@0+ (1,0) [0|0] "" XXX
 SG_ NEW_SIGNAL_2 : 15|18@0+ (1,0) [0|0] "" XXX
 SG_ CHECKSUM : 27|4@0+ (1,0) [0|0] "" XXX
 SG_ COUNTER : 29|2@0+ (1,0) [0|0] "" XXX

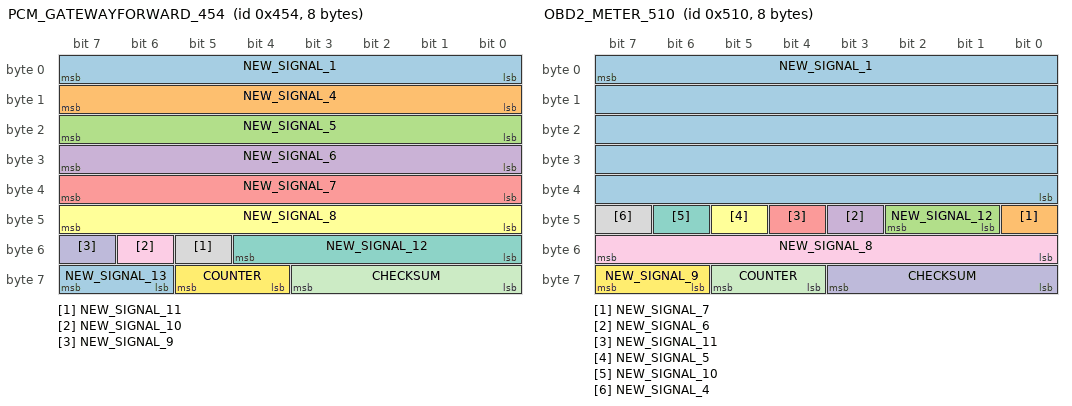
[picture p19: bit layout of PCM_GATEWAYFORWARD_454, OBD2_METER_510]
BO_ 1108 PCM_GATEWAYFORWARD_454: 8 PCM
 SG_ NEW_SIGNAL_1 : 7|8@0+ (1,0) [0|0] "" XXX
 SG_ NEW_SIGNAL_4 : 15|8@0+ (1,0) [0|0] "" XXX
 SG_ NEW_SIGNAL_5 : 23|8@0+ (1,0) [0|0] "" XXX
 SG_ NEW_SIGNAL_6 : 31|8@0+ (1,0) [0|0] "" XXX
 SG_ NEW_SIGNAL_7 : 39|8@0+ (1,0) [0|0] "" XXX
 SG_ NEW_SIGNAL_8 : 47|8@0+ (1,0) [0|0] "" XXX
 SG_ NEW_SIGNAL_12 : 52|5@0+ (1,0) [0|0] "" XXX
 SG_ NEW_SIGNAL_11 : 53|1@0+ (1,0) [0|0] "" XXX
 SG_ NEW_SIGNAL_10 : 54|1@0+ (1,0) [0|0] "" XXX
 SG_ NEW_SIGNAL_9 : 55|1@0+ (1,0) [0|0] "" XXX
 SG_ CHECKSUM : 59|4@0+ (1,0) [0|0] "" XXX
 SG_ COUNTER : 61|2@0+ (1,0) [0|0] "" XXX
 SG_ NEW_SIGNAL_13 : 63|2@0+ (1,0) [0|0] "" XXX

BO_ 1115 OBD2_IDK_45B: 2 XXX
 SG_ NEW_SIGNAL_1 : 7|8@0+ (1,0) [0|0] "" XXX
 SG_ CHECKSUM : 11|4@0+ (1,0) [0|0] "" XXX
 SG_ COUNTER : 13|2@0+ (1,0) [0|0] "" XXX
 SG_ NEW_SIGNAL_2 : 15|2@0+ (1,0) [0|0] "" XXX

BO_ 1125 OBD2_PCM_465: 8 PCM
 SG_ NEW_SIGNAL_1 : 7|48@0+ (1,0) [0|0] "" XXX
 SG_ NEW_SIGNAL_2 : 55|8@0+ (1,0) [0|0] "" XXX
 SG_ CHECKSUM : 59|4@0+ (1,0) [0|0] "" XXX
 SG_ COUNTER : 61|2@0+ (1,0) [0|0] "" XXX
 SG_ NEW_SIGNAL_3 : 63|2@0+ (1,0) [0|0] "" XXX

BO_ 1127 OBD2_PCM_467: 2 PCM
 SG_ NEW_SIGNAL_1 : 7|8@0+ (1,0) [0|0] "" XXX
 SG_ CHECKSUM : 11|4@0+ (1,0) [0|0] "" XXX
 SG_ COUNTER : 13|2@0+ (1,0) [0|0] "" XXX
 SG_ NEW_SIGNAL_2 : 15|2@0+ (1,0) [0|0] "" XXX

BO_ 1296 OBD2_METER_510: 8 METER
 SG_ NEW_SIGNAL_1 : 7|40@0+ (1,0) [0|0] "" XXX
 SG_ NEW_SIGNAL_7 : 40|1@0+ (1,0) [0|0] "" XXX
 SG_ NEW_SIGNAL_12 : 42|2@0+ (1,0) [0|0] "" XXX
 SG_ NEW_SIGNAL_6 : 43|1@0+ (1,0) [0|0] "" XXX
 SG_ NEW_SIGNAL_11 : 44|1@0+ (1,0) [0|0] "" XXX
 SG_ NEW_SIGNAL_5 : 45|1@0+ (1,0) [0|0] "" XXX
 SG_ NEW_SIGNAL_10 : 46|1@0+ (1,0) [0|0] "" XXX
 SG_ NEW_SIGNAL_4 : 47|1@0+ (1,0) [0|0] "" XXX
 SG_ NEW_SIGNAL_8 : 55|8@0+ (1,0) [0|0] "" XXX
 SG_ CHECKSUM : 59|4@0+ (1,0) [0|0] "" XXX
 SG_ COUNTER : 61|2@0+ (1,0) [0|0] "" XXX
 SG_ NEW_SIGNAL_9 : 63|2@0+ (1,0) [0|0] "" XXX

BO_ 1302 METER_516: 8 METER
 SG_ NEW_SIGNAL_2 : 7|8@0+ (1,0) [0|0] "" XXX
 SG_ NEW_SIGNAL_3 : 15|8@0+ (1,0) [0|0] "" XXX
 SG_ NEW_SIGNAL_4 : 23|8@0+ (1,0) [0|0] "" XXX
 SG_ NEW_SIGNAL_5 : 29|6@0+ (1,0) [0|0] "" XXX
 SG_ NEW_SIGNAL_1 : 31|2@0+ (1,0) [0|0] "" XXX
 SG_ NEW_SIGNAL_6 : 39|24@0+ (1,0) [0|0] "" XXX
 SG_ CHECKSUM : 59|4@0+ (1,0) [0|0] "" XXX
 SG_ COUNTER : 61|2@0+ (1,0) [0|0] "" XXX
 SG_ NEW_SIGNAL_7 : 63|2@0+ (1,0) [0|0] "" XXX

BO_ 1322 METER_DTC: 5 METER
 SG_ NEW_SIGNAL_1 : 7|8@0+ (1,0) [0|0] "" XXX
 SG_ NEW_SIGNAL_2 : 15|8@0+ (1,0) [0|0] "" XXX
 SG_ NEW_SIGNAL_3 : 23|8@0+ (1,0) [0|0] "" XXX
 SG_ NEW_SIGNAL_4 : 31|8@0+ (1,0) [0|0] "" XXX
 SG_ CHECKSUM : 35|4@0+ (1,0) [0|0] "" XXX
 SG_ COUNTER : 37|2@0+ (1,0) [0|0] "" XXX
 SG_ NEW_SIGNAL_5 : 39|2@0+ (1,0) [0|0] "" XXX

BO_ 1361 EPS_DTC: 5 EPS
 SG_ NEW_SIGNAL_1 : 7|8@0+ (1,0) [0|0] "" XXX
 SG_ NEW_SIGNAL_2 : 15|8@0+ (1,0) [0|0] "" XXX
 SG_ NEW_SIGNAL_3 : 23|8@0+ (1,0) [0|0] "" XXX
 SG_ NEW_SIGNAL_4 : 31|8@0+ (1,0) [0|0] "" XXX
 SG_ CHECKSUM : 35|4@0+ (1,0) [0|0] "" XXX
 SG_ COUNTER : 37|2@0+ (1,0) [0|0] "" XXX
 SG_ NEW_SIGNAL_5 : 39|2@0+ (1,0) [0|0] "" XXX

BO_ 1365 SRS_DTC: 5 SRS
 SG_ NEW_SIGNAL_1 : 7|8@0+ (1,0) [0|0] "" XXX
 SG_ NEW_SIGNAL_2 : 15|8@0+ (1,0) [0|0] "" XXX
 SG_ NEW_SIGNAL_3 : 23|8@0+ (1,0) [0|0] "" XXX
 SG_ NEW_SIGNAL_4 : 31|8@0+ (1,0) [0|0] "" XXX
 SG_ CHECKSUM : 35|4@0+ (1,0) [0|0] "" XXX
 SG_ COUNTER : 37|2@0+ (1,0) [0|0] "" XXX
 SG_ NEW_SIGNAL_5 : 39|2@0+ (1,0) [0|0] "" XXX

BO_ 1424 VSA_DTC: 5 VSA
 SG_ NEW_SIGNAL_3 : 7|8@0+ (1,0) [0|0] "" XXX
 SG_ NEW_SIGNAL_4 : 15|8@0+ (1,0) [0|0] "" XXX
 SG_ NEW_SIGNAL_5 : 23|8@0+ (1,0) [0|0] "" XXX
 SG_ NEW_SIGNAL_6 : 31|8@0+ (1,0) [0|0] "" XXX
 SG_ CHECKSUM : 35|4@0+ (1,0) [0|0] "" XXX
 SG_ COUNTER : 37|2@0+ (1,0) [0|0] "" XXX
 SG_ NEW_SIGNAL_7 : 39|2@0+ (1,0) [0|0] "" XXX

BO_ 1568 NEW_MSG_620: 2 XXX
 SG_ NEW_SIGNAL_1 : 7|8@0+ (1,0) [0|0] "" XXX
 SG_ NEW_SIGNAL_4 : 11|4@0+ (1,0) [0|0] "" XXX
 SG_ NEW_SIGNAL_3 : 13|2@0+ (1,0) [0|0] "" XXX
 SG_ NEW_SIGNAL_2 : 15|2@0+ (1,0) [0|0] "" XXX

BO_ 1571 NEW_MSG_623: 3 XXX
 SG_ NEW_SIGNAL_1 : 7|8@0+ (1,0) [0|0] "" XXX
 SG_ NEW_SIGNAL_2 : 15|8@0+ (1,0) [0|0] "" XXX
 SG_ NEW_SIGNAL_4 : 19|4@0+ (1,0) [0|0] "" XXX
 SG_ NEW_SIGNAL_3 : 21|2@0+ (1,0) [0|0] "" XXX
 SG_ NEW_SIGNAL_5 : 23|2@0+ (1,0) [0|0] "" XXX

BO_ 1600 RADAR_DTC: 5 RADAR
 SG_ NEW_SIGNAL_3 : 7|8@0+ (1,0) [0|0] "" XXX
 SG_ NEW_SIGNAL_4 : 15|8@0+ (1,0) [0|0] "" XXX
 SG_ NEW_SIGNAL_5 : 23|8@0+ (1,0) [0|0] "" XXX
 SG_ NEW_SIGNAL_6 : 31|8@0+ (1,0) [0|0] "" XXX
 SG_ CHECKSUM : 35|4@0+ (1,0) [0|0] "" XXX
 SG_ COUNTER : 37|2@0+ (1,0) [0|0] "" XXX
 SG_ NEW_SIGNAL_7 : 39|2@0+ (1,0) [0|0] "" XXX

BO_ 1601 RADAR_641: 8 RADAR
 SG_ NEW_SIGNAL_1 : 7|8@0+ (1,0) [0|0] "" XXX
 SG_ NEW_SIGNAL_2 : 15|8@0+ (1,0) [0|0] "" XXX
 SG_ NEW_SIGNAL_3 : 23|8@0+ (1,0) [0|0] "" XXX
 SG_ NEW_SIGNAL_4 : 31|8@0+ (1,0) [0|0] "" XXX
 SG_ NEW_SIGNAL_5 : 39|8@0+ (1,0) [0|0] "" XXX
 SG_ NEW_SIGNAL_6 : 47|8@0+ (1,0) [0|0] "" XXX
 SG_ NEW_SIGNAL_7 : 55|8@0+ (1,0) [0|0] "" XXX
 SG_ CHECKSUM : 59|4@0+ (1,0) [0|0] "" XXX
 SG_ COUNTER : 61|2@0+ (1,0) [0|0] "" XXX
 SG_ NEW_SIGNAL_10 : 63|2@0+ (1,0) [0|0] "" XXX

BO_ 1618 CRV_IDK_652: 5 XXX
 SG_ NEW_SIGNAL_2 : 7|8@0+ (1,0) [0|0] "" XXX
 SG_ NEW_SIGNAL_1 : 15|8@0+ (1,0) [0|0] "" XXX
 SG_ NEW_SIGNAL_3 : 23|8@0+ (1,0) [0|0] "" XXX
 SG_ NEW_SIGNAL_4 : 31|8@0+ (1,0) [0|0] "" XXX
 SG_ CHECKSUM : 35|4@0+ (1,0) [0|0] "" XXX
 SG_ COUNTER : 37|2@0+ (1,0) [0|0] "" XXX
 SG_ IDK : 39|2@0+ (1,0) [0|0] "" XXX

BO_ 1633 PCM_GATEWAYFORWARD_661: 8 PCM
 SG_ NEW_SIGNAL_3 : 7|8@0+ (1,0) [0|0] "" XXX
 SG_ NEW_SIGNAL_4 : 15|8@0+ (1,0) [0|0] "" XXX
 SG_ NEW_SIGNAL_5 : 23|8@0+ (1,0) [0|0] "" XXX
 SG_ NEW_SIGNAL_6 : 31|8@0+ (1,0) [0|0] "" XXX
 SG_ NEW_SIGNAL_7 : 39|8@0+ (1,0) [0|0] "" XXX
 SG_ NEW_SIGNAL_8 : 47|8@0+ (1,0) [0|0] "" XXX
 SG_ NEW_SIGNAL_9 : 55|8@0+ (1,0) [0|0] "" XXX
 SG_ CHECKSUM : 59|4@0+ (1,0) [0|0] "" XXX
 SG_ COUNTER : 61|2@0+ (1,0) [0|0] "" XXX
 SG_ NEW_SIGNAL_10 : 63|2@0+ (1,0) [0|0] "" XXX

BO_ 1652 ACCORD_IDK_674: 8 XXX
 SG_ NEW_SIGNAL_1 : 7|8@0+ (1,0) [0|0] "" XXX
 SG_ NEW_SIGNAL_2 : 15|8@0+ (1,0) [0|0] "" XXX
 SG_ NEW_SIGNAL_3 : 23|8@0+ (1,0) [0|0] "" XXX
 SG_ NEW_SIGNAL_4 : 31|8@0+ (1,0) [0|0] "" XXX
 SG_ NEW_SIGNAL_5 : 39|8@0+ (1,0) [0|0] "" XXX
 SG_ NEW_SIGNAL_6 : 47|8@0+ (1,0) [0|0] "" XXX
 SG_ NEW_SIGNAL_7 : 55|8@0+ (1,0) [0|0] "" XXX
 SG_ NEW_SIGNAL_8 : 63|8@0+ (1,0) [0|0] "" XXX

BO_ 1670 IBCU_DTC_MATRIX: 5 IBCU
 SG_ ERROR_HEX_1 : 7|8@0+ (1,0) [0|0] "" XXX
 SG_ ERROR_HEX_2 : 15|8@0+ (1,0) [0|0] "" XXX
 SG_ ERROR_HEX_3 : 23|8@0+ (1,0) [0|0] "" XXX
 SG_ NEW_SIGNAL_1 : 31|8@0+ (1,0) [0|0] "" XXX
 SG_ CHECKSUM : 35|4@0+ (1,0) [0|0] "" XXX
 SG_ COUNTER : 37|2@0+ (1,0) [0|0] "" XXX
 SG_ NEW_SIGNAL_2 : 39|2@0+ (1,0) [0|0] "" XXX

BO_ 1872 ACC_CAN_CAMERA_STATUS_1: 8 CAM
 SG_ BAT_VOLTAGE : 15|8@0+ (0.1,0) [0|0] "" XXX
 SG_ TEMP_C : 31|8@0+ (1,0) [0|0] "" XXX

BO_ 13274 LKAS_HUD_A: 5 CAM
 SG_ ENABLED : 0|1@0+ (1,0) [0|0] "" XXX
 SG_ LKAS_PROBLEM : 1|1@0+ (1,0) [0|0] "" XXX
 SG_ LKAS_NOW_AVAILABLE : 4|1@0+ (1,0) [0|0] "" XXX
 SG_ RECENT_STATE_CHANGE : 6|1@0+ (1,0) [0|0] "" XXX
 SG_ CAM_TEMP_HIGH : 7|1@0+ (1,0) [0|0] "" XXX
 SG_ STEERING_REQUIRED : 8|1@0+ (1,0) [0|0] "" XXX
 SG_ LANE_DEPARTURE_ALERT : 9|1@0+ (1,0) [0|0] "" XXX
 SG_ SOLID_LANES : 10|1@0+ (1,0) [0|0] "" XXX
 SG_ LKAS_OFF : 11|1@0+ (1,0) [0|0] "" XXX
 SG_ LKAS_PROBLEM_MINI_ICON : 12|1@0+ (1,0) [0|0] "" XXX
 SG_ DTC : 13|1@0+ (1,0) [0|0] "" XXX
 SG_ DASHED_LANES : 14|1@0+ (1,0) [0|0] "" XXX
 SG_ CAM_TEMP_TOO_HOT : 15|1@0+ (1,0) [0|0] "" XXX
 SG_ BEEP : 17|2@0+ (1,0) [0|0] "" XXX
 SG_ DOUBLE_BEEP : 18|1@0+ (1,0) [0|0] "" XXX
 SG_ RDM_ON : 20|1@0+ (1,0) [0|0] "" XXX
 SG_ RDM_PROBLEM : 21|1@0+ (1,0) [0|0] "" XXX
 SG_ LDW_ICON : 22|1@0+ (1,0) [0|0] "" XXX
 SG_ RDM_SETTING : 25|2@0+ (1,0) [0|0] "" XXX
 SG_ CLEAN_WINDSHIELD : 26|1@0+ (1,0) [0|0] "" XXX
 SG_ RDM_OFF : 27|1@0+ (1,0) [0|0] "" XXX
 SG_ RDM_ON_2 : 28|1@0+ (1,0) [0|0] "" XXX
 SG_ LKAS_BEEP_OFF : 30|1@0+ (1,0) [0|0] "" XXX
 SG_ CHECKSUM : 35|4@0+ (1,0) [0|0] "" XXX
 SG_ COUNTER : 37|2@0+ (1,0) [0|0] "" XXX

BO_ 13275 LKAS_HUD_B: 8 CAM
 SG_ ENABLED : 0|1@0+ (1,0) [0|0] "" XXX
 SG_ LKAS_PROBLEM : 1|1@0+ (1,0) [0|0] "" XXX
 SG_ LKAS_NOW_AVAILABLE : 4|1@0+ (1,0) [0|0] "" XXX
 SG_ RECENT_STATE_CHANGE : 6|1@0+ (1,0) [0|0] "" XXX
 SG_ CAM_TEMP_HIGH : 7|1@0+ (1,0) [0|0] "" XXX
 SG_ STEERING_REQUIRED : 8|1@0+ (1,0) [0|0] "" XXX
 SG_ LANE_DEPARTURE_ALERT : 9|1@0+ (1,0) [0|0] "" XXX
 SG_ SOLID_LANES : 10|1@0+ (1,0) [0|0] "" XXX
 SG_ LKAS_OFF : 11|1@0+ (1,0) [0|0] "" XXX
 SG_ LKAS_PROBLEM_MINI_ICON : 12|1@0+ (1,0) [0|0] "" XXX
 SG_ DTC : 13|1@0+ (1,0) [0|0] "" XXX
 SG_ DASHED_LANES : 14|1@0+ (1,0) [0|0] "" XXX
 SG_ CAM_TEMP_TOO_HOT : 15|1@0+ (1,0) [0|0] "" XXX
 SG_ BEEP : 17|2@0+ (1,0) [0|0] "" XXX
 SG_ DOUBLE_BEEP : 18|1@0+ (1,0) [0|0] "" XXX
 SG_ RDM_ON : 20|1@0+ (1,0) [0|0] "" XXX
 SG_ RDM_PROBLEM : 21|1@0+ (1,0) [0|0] "" XXX
 SG_ LDW_ICON : 22|1@0+ (1,0) [0|0] "" XXX
 SG_ RDM_SETTING : 25|2@0+ (1,0) [0|0] "" XXX
 SG_ CLEAN_WINDSHIELD : 26|1@0+ (1,0) [0|0] "" XXX
 SG_ RDM_OFF : 27|1@0+ (1,0) [0|0] "" XXX
 SG_ RDM_ON_2 : 28|1@0+ (1,0) [0|0] "" XXX
 SG_ LKAS_BEEP_OFF : 30|1@0+ (1,0) [0|0] "" XXX
 SG_ RAMP_TO_NO_TORQUE_ON_RELEASE : 36|2@0+ (1,0) [0|0] "" XXX
 SG_ CHECKSUM : 59|4@0+ (1,0) [0|0] "" XXX
 SG_ COUNTER : 61|2@0+ (1,0) [0|0] "" XXX

BO_ 134117888 NEW_MSG_7FE7A00: 8 XXX
 SG_ NEW_SIGNAL_2 : 7|8@0+ (1,0) [0|0] "" XXX
 SG_ NEW_SIGNAL_1 : 39|8@0- (0.01,0) [0|0] "" XXX
 SG_ NEW_SIGNAL_3 : 44|5@0+ (1,0) [0|0] "" XXX

BO_ 318263376 NEW_MSG_12F85050: 6 XXX
 SG_ NEW_SIGNAL_1 : 23|8@0+ (1,0) [0|0] "" XXX

BO_ 417001771 IBCU_ISOTP: 8 IBCU

BO_ 469662262 NEW_MSG_1BFE7A36: 8 XXX
 SG_ NEW_SIGNAL_1 : 7|8@0+ (1,0) [0|0] "" XXX
 SG_ NEW_SIGNAL_2 : 15|8@0+ (1,0) [0|0] "" XXX
 SG_ NEW_SIGNAL_3 : 23|8@0+ (1,0) [0|0] "" XXX
 SG_ NEW_SIGNAL_4 : 31|8@0+ (1,0) [0|0] "" XXX
 SG_ NEW_SIGNAL_5 : 39|8@0+ (1,0) [0|0] "" XXX
 SG_ NEW_SIGNAL_6 : 47|8@0+ (1,0) [0|0] "" XXX
 SG_ interesting1 : 55|8@0+ (1,0) [0|0] "" XXX

BO_ 469662263 NEW_MSG_1BFE7A37: 8 XXX
 SG_ NEW_SIGNAL_2 : 7|8@0+ (1,0) [0|0] "" XXX
 SG_ NEW_SIGNAL_1 : 15|8@0+ (1,0) [0|0] "" XXX
 SG_ NEW_SIGNAL_5 : 39|8@0+ (1,0) [0|0] "" XXX

CM_ SG_ 148 LAT_ACCEL "LEFT=POSTIVE";
CM_ SG_ 148 ROLL "LEFT=POSITIVE,RIGHT=NEGATIVE";
CM_ SG_ 232 SPEED "smoothed";
CM_ SG_ 829 RECENT_STATE_CHANGE "IN LAST 3000MS";
CM_ SG_ 829 RDM_SETTING "0=NORMAL,1=WIDE,2=WARNING_ONLY";
CM_ SG_ 829 RDM_OFF "OR WARNING ONLY";
CM_ SG_ 13274 RECENT_STATE_CHANGE "IN LAST 3000MS";
CM_ SG_ 13274 RDM_SETTING "0=NORMAL,1=WIDE,2=WARNING_ONLY";
CM_ SG_ 13274 RDM_OFF "OR WARNING ONLY";
CM_ SG_ 13275 RECENT_STATE_CHANGE "IN LAST 3000MS";
CM_ SG_ 13275 RDM_SETTING "0=NORMAL,1=WIDE,2=WARNING_ONLY";
CM_ SG_ 13275 RDM_OFF "OR WARNING ONLY";
CM_ SG_ 13275 RAMP_TO_NO_TORQUE_ON_RELEASE "OVER 0-1000MS";
VAL_ 884 ALERT 7 "FUEL_LOW" 0 "NO_ALERT";
VAL_ 927 BLIND_SPOT 1 "RIGHT" 2 "LEFT" 0 "BLANK";
